VERSION "dbc-export 1 2026.26.6.5"

NS_ :

BS_:

BU_: ADSP APB APP APS APSB BB BMS CC CMP CMPD CP DAS DI DIF DIR DPB EPAS3P EPAS3S EPASTP EPASTS EPBL EPBR ESP EVSE FC GTW HCML HCMR HVP IBST ICR IDB LS OCS1P ODIN PARK PCS PCS2 PLG PM PMF PMR PNCD PTC RADC RCM RCM2 RCM3 RCU SCCM SCM SCS SDCR TAS TCU TCU2 TPMS TRCM UDS UI UIS UMC USM V2G VC VCBATT VCBATT0 VCBATT1 VCBATT2 VCCC VCFRONT VCFRONT1 VCFRONT2 VCLEFT VCRIGHT VCSEAT2L VCSEAT2R VCSEC VEH

BO_ 2030 TRCM_alertMatrix: 8 TRCM
 SG_ TRCM_matrixIndex M : 0|4@1+ (1,0) [0|15] "" Vector__XXX
 SG_ TRCM_a001_airbagsDisabled m0 : 4|1@1+ (1,0) [0|1] "" Vector__XXX
 SG_ TRCM_a002_systemDisabled m0 : 5|1@1+ (1,0) [0|1] "" Vector__XXX
 SG_ TRCM_a003_SWAssertion m0 : 6|1@1+ (1,0) [0|1] "" Vector__XXX
 SG_ TRCM_a004_internalFailure m0 : 7|1@1+ (1,0) [0|1] "" Vector__XXX
 SG_ TRCM_a005_CANTXError m0 : 8|1@1+ (1,0) [0|1] "" Vector__XXX
 SG_ TRCM_a006_CANTX_cyclicError m0 : 9|1@1+ (1,0) [0|1] "" Vector__XXX
 SG_ TRCM_a007_chassisChecksumError m0 : 10|1@1+ (1,0) [0|1] "" Vector__XXX
 SG_ TRCM_a008_chassisCounterError m0 : 11|1@1+ (1,0) [0|1] "" Vector__XXX
 SG_ TRCM_a009_partyChecksumError m0 : 12|1@1+ (1,0) [0|1] "" Vector__XXX
 SG_ TRCM_a010_partyCounterError m0 : 13|1@1+ (1,0) [0|1] "" Vector__XXX
 SG_ TRCM_a011_edrDataLocked m0 : 14|1@1+ (1,0) [0|1] "" Vector__XXX
 SG_ TRCM_a012_asm5TemperatureOutside m0 : 15|1@1+ (1,0) [0|1] "" Vector__XXX
 SG_ TRCM_a013_AlertManagerFault m0 : 16|1@1+ (1,0) [0|1] "" Vector__XXX
 SG_ TRCM_a014_asm3TemperatureOutside m0 : 17|1@1+ (1,0) [0|1] "" Vector__XXX
 SG_ TRCM_a015_NVMMError m0 : 18|1@1+ (1,0) [0|1] "" Vector__XXX
 SG_ TRCM_a016_NVMMRecordError m0 : 19|1@1+ (1,0) [0|1] "" Vector__XXX
 SG_ TRCM_a017_asm5TemperatureOutside m0 : 20|1@1+ (1,0) [0|1] "" Vector__XXX
 SG_ TRCM_a018_asm3TemperatureOutside m0 : 21|1@1+ (1,0) [0|1] "" Vector__XXX
 SG_ TRCM_a019_Task500usError m0 : 22|1@1+ (1,0) [0|1] "" Vector__XXX
 SG_ TRCM_a020_asm3ComStatusError m0 : 23|1@1+ (1,0) [0|1] "" Vector__XXX
 SG_ TRCM_a021_TaskSchedulerError m0 : 24|1@1+ (1,0) [0|1] "" Vector__XXX
 SG_ TRCM_a022_TaskInitError m0 : 25|1@1+ (1,0) [0|1] "" Vector__XXX
 SG_ TRCM_a023_asm3ArsStatusXError m0 : 26|1@1+ (1,0) [0|1] "" Vector__XXX
 SG_ TRCM_a024_asm3AccStatusError m0 : 27|1@1+ (1,0) [0|1] "" Vector__XXX
 SG_ TRCM_a025_CHCANBusFaults m0 : 28|1@1+ (1,0) [0|1] "" Vector__XXX
 SG_ TRCM_a026_airbagAsicDiagnosticFa m0 : 29|1@1+ (1,0) [0|1] "" Vector__XXX
 SG_ TRCM_a027_airbagAsicDeploymentDi m0 : 30|1@1+ (1,0) [0|1] "" Vector__XXX
 SG_ TRCM_a028_chassisLengthError m0 : 31|1@1+ (1,0) [0|1] "" Vector__XXX
 SG_ TRCM_a030_ECULogUploadRequest m0 : 33|1@1+ (1,0) [0|1] "" Vector__XXX
 SG_ TRCM_a031_UDSActive m0 : 34|1@1+ (1,0) [0|1] "" Vector__XXX
 SG_ TRCM_a032_ScrollCreated m0 : 35|1@1+ (1,0) [0|1] "" Vector__XXX
 SG_ TRCM_a033_HercLogCreated m0 : 36|1@1+ (1,0) [0|1] "" Vector__XXX
 SG_ TRCM_a034_apClipTrigger m0 : 37|1@1+ (1,0) [0|1] "" Vector__XXX
 SG_ TRCM_a035_hvDisconnectCommanded m0 : 38|1@1+ (1,0) [0|1] "" Vector__XXX
 SG_ TRCM_a036_crashDetected m0 : 39|1@1+ (1,0) [0|1] "" Vector__XXX
 SG_ TRCM_a037_nearDeploy m0 : 40|1@1+ (1,0) [0|1] "" Vector__XXX
 SG_ TRCM_a038_ens1Degraded m0 : 41|1@1+ (1,0) [0|1] "" Vector__XXX
 SG_ TRCM_a039_ens2Degraded m0 : 42|1@1+ (1,0) [0|1] "" Vector__XXX
 SG_ TRCM_a040_task500usOverrunDebug m0 : 43|1@1+ (1,0) [0|1] "" Vector__XXX
 SG_ TRCM_a041_HighCPULoad m0 : 44|1@1+ (1,0) [0|1] "" Vector__XXX
 SG_ TRCM_a042_HighStackUsage m0 : 45|1@1+ (1,0) [0|1] "" Vector__XXX
 SG_ TRCM_a043_Task1msError m0 : 46|1@1+ (1,0) [0|1] "" Vector__XXX
 SG_ TRCM_a044_Task10msError m0 : 47|1@1+ (1,0) [0|1] "" Vector__XXX
 SG_ TRCM_a045_Task100msError m0 : 48|1@1+ (1,0) [0|1] "" Vector__XXX
 SG_ TRCM_a046_Task1000msError m0 : 49|1@1+ (1,0) [0|1] "" Vector__XXX
 SG_ TRCM_a047_vinNotLearned m0 : 50|1@1+ (1,0) [0|1] "" Vector__XXX
 SG_ TRCM_a048_vinMismatch m0 : 51|1@1+ (1,0) [0|1] "" Vector__XXX
 SG_ TRCM_a049_nvmDebugInfo m0 : 52|1@1+ (1,0) [0|1] "" Vector__XXX
 SG_ TRCM_a050_partyLengthError m0 : 53|1@1+ (1,0) [0|1] "" Vector__XXX
 SG_ TRCM_a051_systemSelfTestTimeout m0 : 54|1@1+ (1,0) [0|1] "" Vector__XXX
 SG_ TRCM_a057_HVP_MIA m0 : 60|1@1+ (1,0) [0|1] "" Vector__XXX
 SG_ TRCM_a058_inputRHighSyncDebug m0 : 61|1@1+ (1,0) [0|1] "" Vector__XXX
 SG_ TRCM_a059_inputResistanceHigh m0 : 62|1@1+ (1,0) [0|1] "" Vector__XXX
 SG_ TRCM_a060_engineeringBuild m0 : 63|1@1+ (1,0) [0|1] "" Vector__XXX
 SG_ TRCM_a061_XCPConnected m1 : 4|1@1+ (1,0) [0|1] "" Vector__XXX
 SG_ TRCM_a062_XCPWasConnected m1 : 5|1@1+ (1,0) [0|1] "" Vector__XXX
 SG_ TRCM_a063_SwitchFault m1 : 6|1@1+ (1,0) [0|1] "" Vector__XXX
 SG_ TRCM_a064_busSleepReqTimeout m1 : 7|1@1+ (1,0) [0|1] "" Vector__XXX
 SG_ TRCM_a065_vSafingFetUnderVoltage m1 : 8|1@1+ (1,0) [0|1] "" Vector__XXX
 SG_ TRCM_a066_leftPowerIssue m1 : 9|1@1+ (1,0) [0|1] "" Vector__XXX
 SG_ TRCM_a067_rightPowerIssue m1 : 10|1@1+ (1,0) [0|1] "" Vector__XXX
 SG_ TRCM_a068_vBusCUnderVoltage m1 : 11|1@1+ (1,0) [0|1] "" Vector__XXX
 SG_ TRCM_a069_swAppBoot m1 : 12|1@1+ (1,0) [0|1] "" Vector__XXX
 SG_ TRCM_a070_asm3StatusError m1 : 13|1@1+ (1,0) [0|1] "" Vector__XXX
 SG_ TRCM_a071_asm3DeviceFaulted m1 : 14|1@1+ (1,0) [0|1] "" Vector__XXX
 SG_ TRCM_a072_ais2120StatusError m1 : 15|1@1+ (1,0) [0|1] "" Vector__XXX
 SG_ TRCM_a073_ais2120DeviceFaulted m1 : 16|1@1+ (1,0) [0|1] "" Vector__XXX
 SG_ TRCM_a074_ais2120SelfTestXPositi m1 : 17|1@1+ (1,0) [0|1] "" Vector__XXX
 SG_ TRCM_a075_ais2120SelfTestXNegati m1 : 18|1@1+ (1,0) [0|1] "" Vector__XXX
 SG_ TRCM_a076_ais2120SelfTestYPositi m1 : 19|1@1+ (1,0) [0|1] "" Vector__XXX
 SG_ TRCM_a077_ais2120SelfTestYNegati m1 : 20|1@1+ (1,0) [0|1] "" Vector__XXX
 SG_ TRCM_a078_imuSensorSignalMonitor m1 : 21|1@1+ (1,0) [0|1] "" Vector__XXX
 SG_ TRCM_a081_powerLossDetected m1 : 24|1@1+ (1,0) [0|1] "" Vector__XXX
 SG_ TRCM_a082_VCRIGHT_IPC_MIA m1 : 25|1@1+ (1,0) [0|1] "" Vector__XXX
 SG_ TRCM_a083_VCLEFT_IPC_MIA m1 : 26|1@1+ (1,0) [0|1] "" Vector__XXX
 SG_ TRCM_a084_TPMS_MIA m1 : 27|1@1+ (1,0) [0|1] "" Vector__XXX
 SG_ TRCM_a085_CCCM_MIA m1 : 28|1@1+ (1,0) [0|1] "" Vector__XXX
 SG_ TRCM_a086_VCBATT_MIA m1 : 29|1@1+ (1,0) [0|1] "" Vector__XXX
 SG_ TRCM_a087_DIREL_MIA m1 : 30|1@1+ (1,0) [0|1] "" Vector__XXX
 SG_ TRCM_a088_DIRER_MIA m1 : 31|1@1+ (1,0) [0|1] "" Vector__XXX
 SG_ TRCM_a089_IBST_MIA m1 : 32|1@1+ (1,0) [0|1] "" Vector__XXX
 SG_ TRCM_a090_APS_MIA m1 : 33|1@1+ (1,0) [0|1] "" Vector__XXX
 SG_ TRCM_a091_CMPD_MIA m1 : 34|1@1+ (1,0) [0|1] "" Vector__XXX
 SG_ TRCM_a092_VCSEATD_MIA m1 : 35|1@1+ (1,0) [0|1] "" Vector__XXX
 SG_ TRCM_a093_VCSEATP_MIA m1 : 36|1@1+ (1,0) [0|1] "" Vector__XXX
 SG_ TRCM_a094_EPAS3P_MIA m1 : 37|1@1+ (1,0) [0|1] "" Vector__XXX
 SG_ TRCM_a095_CHG_MIA m1 : 38|1@1+ (1,0) [0|1] "" Vector__XXX
 SG_ TRCM_a096_OCS1P_MIA m1 : 39|1@1+ (1,0) [0|1] "" Vector__XXX
 SG_ TRCM_a097_CMP_MIA m1 : 40|1@1+ (1,0) [0|1] "" Vector__XXX
 SG_ TRCM_a098_DIR_MIA m1 : 41|1@1+ (1,0) [0|1] "" Vector__XXX
 SG_ TRCM_a099_PARK_MIA m1 : 42|1@1+ (1,0) [0|1] "" Vector__XXX
 SG_ TRCM_a100_CANbus_MIA m1 : 43|1@1+ (1,0) [0|1] "" Vector__XXX
 SG_ TRCM_a101_PM_MIA m1 : 44|1@1+ (1,0) [0|1] "" Vector__XXX
 SG_ TRCM_a102_PTC_MIA m1 : 45|1@1+ (1,0) [0|1] "" Vector__XXX
 SG_ TRCM_a103_CP_MIA m1 : 46|1@1+ (1,0) [0|1] "" Vector__XXX
 SG_ TRCM_a104_DAS_MIA m1 : 47|1@1+ (1,0) [0|1] "" Vector__XXX
 SG_ TRCM_a105_TAS_MIA m1 : 48|1@1+ (1,0) [0|1] "" Vector__XXX
 SG_ TRCM_a106_PCS_MIA m1 : 49|1@1+ (1,0) [0|1] "" Vector__XXX
 SG_ TRCM_a107_BMS_MIA m1 : 50|1@1+ (1,0) [0|1] "" Vector__XXX
 SG_ TRCM_a108_DIF_MIA m1 : 51|1@1+ (1,0) [0|1] "" Vector__XXX
 SG_ TRCM_a109_RCM_MIA m1 : 52|1@1+ (1,0) [0|1] "" Vector__XXX
 SG_ TRCM_a110_GTW_MIA m1 : 53|1@1+ (1,0) [0|1] "" Vector__XXX
 SG_ TRCM_a111_EPBR_MIA m1 : 54|1@1+ (1,0) [0|1] "" Vector__XXX
 SG_ TRCM_a112_EPBL_MIA m1 : 55|1@1+ (1,0) [0|1] "" Vector__XXX
 SG_ TRCM_a113_UI_MIA m1 : 56|1@1+ (1,0) [0|1] "" Vector__XXX
 SG_ TRCM_a114_ESP_MIA m1 : 57|1@1+ (1,0) [0|1] "" Vector__XXX
 SG_ TRCM_a115_VCSEC_MIA m1 : 58|1@1+ (1,0) [0|1] "" Vector__XXX
 SG_ TRCM_a116_VCRIGHT_MIA m1 : 59|1@1+ (1,0) [0|1] "" Vector__XXX
 SG_ TRCM_a117_VCLEFT_MIA m1 : 60|1@1+ (1,0) [0|1] "" Vector__XXX
 SG_ TRCM_a118_VCFRONT_MIA m1 : 61|1@1+ (1,0) [0|1] "" Vector__XXX
 SG_ TRCM_a119_SCCM_MIA m1 : 62|1@1+ (1,0) [0|1] "" Vector__XXX
 SG_ TRCM_a120_DI_DRIVE_MIA m1 : 63|1@1+ (1,0) [0|1] "" Vector__XXX
 SG_ TRCM_a121_buckleStatusFrontLeftS m2 : 4|1@1+ (1,0) [0|1] "" Vector__XXX
 SG_ TRCM_a122_buckleStatusFrontRight m2 : 5|1@1+ (1,0) [0|1] "" Vector__XXX
 SG_ TRCM_a123_buckleStatusRearLeftSi m2 : 6|1@1+ (1,0) [0|1] "" Vector__XXX
 SG_ TRCM_a124_buckleStatusRearRightS m2 : 7|1@1+ (1,0) [0|1] "" Vector__XXX
 SG_ TRCM_a125_occupantClassification m2 : 8|1@1+ (1,0) [0|1] "" Vector__XXX
 SG_ TRCM_a126_seatTrackPositionLeftS m2 : 9|1@1+ (1,0) [0|1] "" Vector__XXX
 SG_ TRCM_a127_seatTrackPositionRight m2 : 10|1@1+ (1,0) [0|1] "" Vector__XXX
 SG_ TRCM_a135_asm5StatusError m2 : 18|1@1+ (1,0) [0|1] "" Vector__XXX
 SG_ TRCM_a136_asm5DeviceFaulted m2 : 19|1@1+ (1,0) [0|1] "" Vector__XXX
 SG_ TRCM_a137_ext1AsicSnoopTestFaile m2 : 20|1@1+ (1,0) [0|1] "" Vector__XXX
 SG_ TRCM_a138_ext2AsicSnoopTestFaile m2 : 21|1@1+ (1,0) [0|1] "" Vector__XXX
 SG_ TRCM_a145_frontCenterAccelReport m2 : 28|1@1+ (1,0) [0|1] "" Vector__XXX
 SG_ TRCM_a146_frontCenterAccelGenera m2 : 29|1@1+ (1,0) [0|1] "" Vector__XXX
 SG_ TRCM_a147_frontCenterAccelElectr m2 : 30|1@1+ (1,0) [0|1] "" Vector__XXX
 SG_ TRCM_a148_frontCenterAccelConfig m2 : 31|1@1+ (1,0) [0|1] "" Vector__XXX
 SG_ TRCM_a149_frontCenterAccelSignal m2 : 32|1@1+ (1,0) [0|1] "" Vector__XXX
 SG_ TRCM_a150_frontLeftAccelReported m2 : 33|1@1+ (1,0) [0|1] "" Vector__XXX
 SG_ TRCM_a151_frontLeftAccelGeneralI m2 : 34|1@1+ (1,0) [0|1] "" Vector__XXX
 SG_ TRCM_a152_frontLeftAccelElectric m2 : 35|1@1+ (1,0) [0|1] "" Vector__XXX
 SG_ TRCM_a153_frontLeftAccelConfigEr m2 : 36|1@1+ (1,0) [0|1] "" Vector__XXX
 SG_ TRCM_a154_frontLeftAccelSignalMo m2 : 37|1@1+ (1,0) [0|1] "" Vector__XXX
 SG_ TRCM_a155_frontLeftDoorPressureR m2 : 38|1@1+ (1,0) [0|1] "" Vector__XXX
 SG_ TRCM_a156_frontLeftDoorPressureG m2 : 39|1@1+ (1,0) [0|1] "" Vector__XXX
 SG_ TRCM_a157_frontLeftDoorPressureE m2 : 40|1@1+ (1,0) [0|1] "" Vector__XXX
 SG_ TRCM_a158_frontLeftDoorPressureC m2 : 41|1@1+ (1,0) [0|1] "" Vector__XXX
 SG_ TRCM_a159_frontLeftDoorPressureS m2 : 42|1@1+ (1,0) [0|1] "" Vector__XXX
 SG_ TRCM_a160_frontRightAccelReporte m2 : 43|1@1+ (1,0) [0|1] "" Vector__XXX
 SG_ TRCM_a161_frontRightAccelGeneral m2 : 44|1@1+ (1,0) [0|1] "" Vector__XXX
 SG_ TRCM_a162_frontRightAccelElectri m2 : 45|1@1+ (1,0) [0|1] "" Vector__XXX
 SG_ TRCM_a163_frontRightAccelConfigE m2 : 46|1@1+ (1,0) [0|1] "" Vector__XXX
 SG_ TRCM_a164_frontRightAccelSignalM m2 : 47|1@1+ (1,0) [0|1] "" Vector__XXX
 SG_ TRCM_a165_frontRightDoorPressure m2 : 48|1@1+ (1,0) [0|1] "" Vector__XXX
 SG_ TRCM_a166_frontRightDoorPressure m2 : 49|1@1+ (1,0) [0|1] "" Vector__XXX
 SG_ TRCM_a167_frontRightDoorPressure m2 : 50|1@1+ (1,0) [0|1] "" Vector__XXX
 SG_ TRCM_a168_frontRightDoorPressure m2 : 51|1@1+ (1,0) [0|1] "" Vector__XXX
 SG_ TRCM_a169_frontRightDoorPressure m2 : 52|1@1+ (1,0) [0|1] "" Vector__XXX
 SG_ TRCM_a170_leftBPillarAccelReport m2 : 53|1@1+ (1,0) [0|1] "" Vector__XXX
 SG_ TRCM_a171_leftBPillarAccelGenera m2 : 54|1@1+ (1,0) [0|1] "" Vector__XXX
 SG_ TRCM_a172_leftBPillarAccelElectr m2 : 55|1@1+ (1,0) [0|1] "" Vector__XXX
 SG_ TRCM_a173_leftBPillarAccelConfig m2 : 56|1@1+ (1,0) [0|1] "" Vector__XXX
 SG_ TRCM_a174_leftBPillarAccelSignal m2 : 57|1@1+ (1,0) [0|1] "" Vector__XXX
 SG_ TRCM_a175_leftCPillarAccelReport m2 : 58|1@1+ (1,0) [0|1] "" Vector__XXX
 SG_ TRCM_a176_leftCPillarAccelGenera m2 : 59|1@1+ (1,0) [0|1] "" Vector__XXX
 SG_ TRCM_a177_leftCPillarAccelElectr m2 : 60|1@1+ (1,0) [0|1] "" Vector__XXX
 SG_ TRCM_a178_leftCPillarAccelConfig m2 : 61|1@1+ (1,0) [0|1] "" Vector__XXX
 SG_ TRCM_a179_leftCPillarAccelSignal m2 : 62|1@1+ (1,0) [0|1] "" Vector__XXX
 SG_ TRCM_a190_rearLeftDoorPressureRe m3 : 13|1@1+ (1,0) [0|1] "" Vector__XXX
 SG_ TRCM_a191_rearLeftDoorPressureGe m3 : 14|1@1+ (1,0) [0|1] "" Vector__XXX
 SG_ TRCM_a192_rearLeftDoorPressureEl m3 : 15|1@1+ (1,0) [0|1] "" Vector__XXX
 SG_ TRCM_a193_rearLeftDoorPressureCo m3 : 16|1@1+ (1,0) [0|1] "" Vector__XXX
 SG_ TRCM_a194_rearLeftDoorPressureSi m3 : 17|1@1+ (1,0) [0|1] "" Vector__XXX
 SG_ TRCM_a195_rearRightDoorPressureR m3 : 18|1@1+ (1,0) [0|1] "" Vector__XXX
 SG_ TRCM_a196_rearRightDoorPressureG m3 : 19|1@1+ (1,0) [0|1] "" Vector__XXX
 SG_ TRCM_a197_rearRightDoorPressureE m3 : 20|1@1+ (1,0) [0|1] "" Vector__XXX
 SG_ TRCM_a198_rearRightDoorPressureC m3 : 21|1@1+ (1,0) [0|1] "" Vector__XXX
 SG_ TRCM_a199_rearRightDoorPressureS m3 : 22|1@1+ (1,0) [0|1] "" Vector__XXX
 SG_ TRCM_a200_rightBPillarAccelRepor m3 : 23|1@1+ (1,0) [0|1] "" Vector__XXX
 SG_ TRCM_a201_rightBPillarAccelGener m3 : 24|1@1+ (1,0) [0|1] "" Vector__XXX
 SG_ TRCM_a202_rightBPillarAccelElect m3 : 25|1@1+ (1,0) [0|1] "" Vector__XXX
 SG_ TRCM_a203_rightBPillarAccelConfi m3 : 26|1@1+ (1,0) [0|1] "" Vector__XXX
 SG_ TRCM_a204_rightBPillarAccelSigna m3 : 27|1@1+ (1,0) [0|1] "" Vector__XXX
 SG_ TRCM_a205_rightCPillarAccelRepor m3 : 28|1@1+ (1,0) [0|1] "" Vector__XXX
 SG_ TRCM_a206_rightCPillarAccelGener m3 : 29|1@1+ (1,0) [0|1] "" Vector__XXX
 SG_ TRCM_a207_rightCPillarAccelElect m3 : 30|1@1+ (1,0) [0|1] "" Vector__XXX
 SG_ TRCM_a208_rightCPillarAccelConfi m3 : 31|1@1+ (1,0) [0|1] "" Vector__XXX
 SG_ TRCM_a209_rightCPillarAccelSigna m3 : 32|1@1+ (1,0) [0|1] "" Vector__XXX
 SG_ TRCM_a272_asm5ComStatusError m4 : 35|1@1+ (1,0) [0|1] "" Vector__XXX
 SG_ TRCM_a273_asm5ArsStatusXError m4 : 36|1@1+ (1,0) [0|1] "" Vector__XXX
 SG_ TRCM_a274_asm5ArsStatusZError m4 : 37|1@1+ (1,0) [0|1] "" Vector__XXX
 SG_ TRCM_a275_asm5AccStatusError m4 : 38|1@1+ (1,0) [0|1] "" Vector__XXX
 SG_ TRCM_a276_watchdogStatus m4 : 39|1@1+ (1,0) [0|1] "" Vector__XXX
 SG_ TRCM_a278_safingEngine0Armed m4 : 41|1@1+ (1,0) [0|1] "" Vector__XXX
 SG_ TRCM_a279_safingEngine1Armed m4 : 42|1@1+ (1,0) [0|1] "" Vector__XXX
 SG_ TRCM_a280_safingEngine2Armed m4 : 43|1@1+ (1,0) [0|1] "" Vector__XXX
 SG_ TRCM_a281_safingEngine3Armed m4 : 44|1@1+ (1,0) [0|1] "" Vector__XXX
 SG_ TRCM_a282_safingEngine4Armed m4 : 45|1@1+ (1,0) [0|1] "" Vector__XXX
 SG_ TRCM_a283_safingEngine5Armed m4 : 46|1@1+ (1,0) [0|1] "" Vector__XXX
 SG_ TRCM_a284_safingEngine6Armed m4 : 47|1@1+ (1,0) [0|1] "" Vector__XXX
 SG_ TRCM_a285_safingEngine7Armed m4 : 48|1@1+ (1,0) [0|1] "" Vector__XXX
 SG_ TRCM_a286_safingEngine8Armed m4 : 49|1@1+ (1,0) [0|1] "" Vector__XXX
 SG_ TRCM_a287_safingEngine9Armed m4 : 50|1@1+ (1,0) [0|1] "" Vector__XXX
 SG_ TRCM_a288_safingEngine10Armed m4 : 51|1@1+ (1,0) [0|1] "" Vector__XXX
 SG_ TRCM_a289_safingEngine11Armed m4 : 52|1@1+ (1,0) [0|1] "" Vector__XXX
 SG_ TRCM_a290_safingEngine12Armed m4 : 53|1@1+ (1,0) [0|1] "" Vector__XXX
 SG_ TRCM_a291_safingEngine13Armed m4 : 54|1@1+ (1,0) [0|1] "" Vector__XXX
 SG_ TRCM_a292_safingEngine14Armed m4 : 55|1@1+ (1,0) [0|1] "" Vector__XXX
 SG_ TRCM_a293_safingEngine15Armed m4 : 56|1@1+ (1,0) [0|1] "" Vector__XXX
 SG_ TRCM_a294_safingEngine16Armed m4 : 57|1@1+ (1,0) [0|1] "" Vector__XXX
 SG_ TRCM_a295_safingEngine17Armed m4 : 58|1@1+ (1,0) [0|1] "" Vector__XXX
 SG_ TRCM_a296_safingEngine18Armed m4 : 59|1@1+ (1,0) [0|1] "" Vector__XXX
 SG_ TRCM_a297_safingEngine19Armed m4 : 60|1@1+ (1,0) [0|1] "" Vector__XXX
 SG_ TRCM_a298_safingEngine20Armed m4 : 61|1@1+ (1,0) [0|1] "" Vector__XXX
 SG_ TRCM_a299_safingEngine21Armed m4 : 62|1@1+ (1,0) [0|1] "" Vector__XXX
 SG_ TRCM_a300_driverAirbagStage1Supp m4 : 63|1@1+ (1,0) [0|1] "" Vector__XXX
 SG_ TRCM_a301_passengerAirbagStage1S m5 : 4|1@1+ (1,0) [0|1] "" Vector__XXX
 SG_ TRCM_a302_driverAirbagStage2Supp m5 : 5|1@1+ (1,0) [0|1] "" Vector__XXX
 SG_ TRCM_a303_driverAirbagActiveVent m5 : 6|1@1+ (1,0) [0|1] "" Vector__XXX
 SG_ TRCM_a304_passengerAirbagStage2S m5 : 7|1@1+ (1,0) [0|1] "" Vector__XXX
 SG_ TRCM_a305_passengerAirbagActiveV m5 : 8|1@1+ (1,0) [0|1] "" Vector__XXX
 SG_ TRCM_a306_inboardSeatAirbagSuppr m5 : 9|1@1+ (1,0) [0|1] "" Vector__XXX
 SG_ TRCM_a308_kneeAirbagLeftSuppress m5 : 11|1@1+ (1,0) [0|1] "" Vector__XXX
 SG_ TRCM_a309_kneeAirbagRightSuppres m5 : 12|1@1+ (1,0) [0|1] "" Vector__XXX
 SG_ TRCM_a310_curtainAirbagLeftSuppr m5 : 13|1@1+ (1,0) [0|1] "" Vector__XXX
 SG_ TRCM_a311_curtainAirbagRightSupp m5 : 14|1@1+ (1,0) [0|1] "" Vector__XXX
 SG_ TRCM_a312_seatbeltLoadLimiterFro m5 : 15|1@1+ (1,0) [0|1] "" Vector__XXX
 SG_ TRCM_a313_seatbeltLoadLimiterFro m5 : 16|1@1+ (1,0) [0|1] "" Vector__XXX
 SG_ TRCM_a314_seatbeltShoulderPreten m5 : 17|1@1+ (1,0) [0|1] "" Vector__XXX
 SG_ TRCM_a315_seatbeltShoulderPreten m5 : 18|1@1+ (1,0) [0|1] "" Vector__XXX
 SG_ TRCM_a316_seatbeltLapPretensione m5 : 19|1@1+ (1,0) [0|1] "" Vector__XXX
 SG_ TRCM_a317_seatbeltLapPretensione m5 : 20|1@1+ (1,0) [0|1] "" Vector__XXX
 SG_ TRCM_a318_outboardSeatAirbagLeft m5 : 21|1@1+ (1,0) [0|1] "" Vector__XXX
 SG_ TRCM_a319_outboardSeatAirbagRigh m5 : 22|1@1+ (1,0) [0|1] "" Vector__XXX
 SG_ TRCM_a320_hoodLifterLeftSuppress m5 : 23|1@1+ (1,0) [0|1] "" Vector__XXX
 SG_ TRCM_a321_hoodLifterRightSuppres m5 : 24|1@1+ (1,0) [0|1] "" Vector__XXX
 SG_ TRCM_a322_seatbeltShoulderPreten m5 : 25|1@1+ (1,0) [0|1] "" Vector__XXX
 SG_ TRCM_a323_seatbeltShoulderPreten m5 : 26|1@1+ (1,0) [0|1] "" Vector__XXX
 SG_ TRCM_a332_driverAirbagStage1Depl m5 : 35|1@1+ (1,0) [0|1] "" Vector__XXX
 SG_ TRCM_a333_passengerAirbagStage1D m5 : 36|1@1+ (1,0) [0|1] "" Vector__XXX
 SG_ TRCM_a334_driverAirbagStage2Depl m5 : 37|1@1+ (1,0) [0|1] "" Vector__XXX
 SG_ TRCM_a335_driverAirbagActiveVent m5 : 38|1@1+ (1,0) [0|1] "" Vector__XXX
 SG_ TRCM_a336_passengerAirbagStage2D m5 : 39|1@1+ (1,0) [0|1] "" Vector__XXX
 SG_ TRCM_a337_passengerAirbagActiveV m5 : 40|1@1+ (1,0) [0|1] "" Vector__XXX
 SG_ TRCM_a338_inboardSeatAirbagDeplo m5 : 41|1@1+ (1,0) [0|1] "" Vector__XXX
 SG_ TRCM_a340_kneeAirbagLeftDeployed m5 : 43|1@1+ (1,0) [0|1] "" Vector__XXX
 SG_ TRCM_a341_kneeAirbagRightDeploye m5 : 44|1@1+ (1,0) [0|1] "" Vector__XXX
 SG_ TRCM_a342_curtainAirbagLeftDeplo m5 : 45|1@1+ (1,0) [0|1] "" Vector__XXX
 SG_ TRCM_a343_curtainAirbagRightDepl m5 : 46|1@1+ (1,0) [0|1] "" Vector__XXX
 SG_ TRCM_a344_seatbeltLoadLimiterFro m5 : 47|1@1+ (1,0) [0|1] "" Vector__XXX
 SG_ TRCM_a345_seatbeltLoadLimiterFro m5 : 48|1@1+ (1,0) [0|1] "" Vector__XXX
 SG_ TRCM_a346_seatbeltShoulderPreten m5 : 49|1@1+ (1,0) [0|1] "" Vector__XXX
 SG_ TRCM_a347_seatbeltShoulderPreten m5 : 50|1@1+ (1,0) [0|1] "" Vector__XXX
 SG_ TRCM_a348_seatbeltLapPretensione m5 : 51|1@1+ (1,0) [0|1] "" Vector__XXX
 SG_ TRCM_a349_seatbeltLapPretensione m5 : 52|1@1+ (1,0) [0|1] "" Vector__XXX
 SG_ TRCM_a350_outboardSeatAirbagLeft m5 : 53|1@1+ (1,0) [0|1] "" Vector__XXX
 SG_ TRCM_a351_outboardSeatAirbagRigh m5 : 54|1@1+ (1,0) [0|1] "" Vector__XXX
 SG_ TRCM_a352_hoodLifterLeftDeployed m5 : 55|1@1+ (1,0) [0|1] "" Vector__XXX
 SG_ TRCM_a353_hoodLifterRightDeploye m5 : 56|1@1+ (1,0) [0|1] "" Vector__XXX
 SG_ TRCM_a354_seatbeltShoulderPreten m5 : 57|1@1+ (1,0) [0|1] "" Vector__XXX
 SG_ TRCM_a355_seatbeltShoulderPreten m5 : 58|1@1+ (1,0) [0|1] "" Vector__XXX
 SG_ TRCM_a364_safingEngine0NoValidDa m6 : 7|1@1+ (1,0) [0|1] "" Vector__XXX
 SG_ TRCM_a365_safingEngine1NoValidDa m6 : 8|1@1+ (1,0) [0|1] "" Vector__XXX
 SG_ TRCM_a366_safingEngine2NoValidDa m6 : 9|1@1+ (1,0) [0|1] "" Vector__XXX
 SG_ TRCM_a367_safingEngine3NoValidDa m6 : 10|1@1+ (1,0) [0|1] "" Vector__XXX
 SG_ TRCM_a368_safingEngine4NoValidDa m6 : 11|1@1+ (1,0) [0|1] "" Vector__XXX
 SG_ TRCM_a369_safingEngine5NoValidDa m6 : 12|1@1+ (1,0) [0|1] "" Vector__XXX
 SG_ TRCM_a370_safingEngine6NoValidDa m6 : 13|1@1+ (1,0) [0|1] "" Vector__XXX
 SG_ TRCM_a371_safingEngine7NoValidDa m6 : 14|1@1+ (1,0) [0|1] "" Vector__XXX
 SG_ TRCM_a372_safingEngine8NoValidDa m6 : 15|1@1+ (1,0) [0|1] "" Vector__XXX
 SG_ TRCM_a373_safingEngine9NoValidDa m6 : 16|1@1+ (1,0) [0|1] "" Vector__XXX
 SG_ TRCM_a374_safingEngine10NoValidD m6 : 17|1@1+ (1,0) [0|1] "" Vector__XXX
 SG_ TRCM_a375_safingEngine11NoValidD m6 : 18|1@1+ (1,0) [0|1] "" Vector__XXX
 SG_ TRCM_a376_safingEngine12NoValidD m6 : 19|1@1+ (1,0) [0|1] "" Vector__XXX
 SG_ TRCM_a377_safingEngine13NoValidD m6 : 20|1@1+ (1,0) [0|1] "" Vector__XXX
 SG_ TRCM_a378_safingEngine14NoValidD m6 : 21|1@1+ (1,0) [0|1] "" Vector__XXX
 SG_ TRCM_a379_safingEngine15NoValidD m6 : 22|1@1+ (1,0) [0|1] "" Vector__XXX
 SG_ TRCM_a380_safingEngine16NoValidD m6 : 23|1@1+ (1,0) [0|1] "" Vector__XXX
 SG_ TRCM_a381_safingEngine17NoValidD m6 : 24|1@1+ (1,0) [0|1] "" Vector__XXX
 SG_ TRCM_a382_safingEngine18NoValidD m6 : 25|1@1+ (1,0) [0|1] "" Vector__XXX
 SG_ TRCM_a383_safingEngine19NoValidD m6 : 26|1@1+ (1,0) [0|1] "" Vector__XXX
 SG_ TRCM_a384_safingEngine20NoValidD m6 : 27|1@1+ (1,0) [0|1] "" Vector__XXX
 SG_ TRCM_a385_safingEngine21NoValidD m6 : 28|1@1+ (1,0) [0|1] "" Vector__XXX
 SG_ TRCM_a387_primaryAsicResetSource m6 : 30|1@1+ (1,0) [0|1] "" Vector__XXX
 SG_ TRCM_a388_cpuLoadHigh m6 : 31|1@1+ (1,0) [0|1] "" Vector__XXX
 SG_ TRCM_a389_asicPwrStatusError m6 : 32|1@1+ (1,0) [0|1] "" Vector__XXX
 SG_ TRCM_a390_systemAsicClockOrOpera m6 : 33|1@1+ (1,0) [0|1] "" Vector__XXX
 SG_ TRCM_a391_extAsic1ClockOrOperati m6 : 34|1@1+ (1,0) [0|1] "" Vector__XXX
 SG_ TRCM_a392_extAsic2ClockOrOperati m6 : 35|1@1+ (1,0) [0|1] "" Vector__XXX
 SG_ TRCM_a393_depAdcConvertRatioErro m6 : 36|1@1+ (1,0) [0|1] "" Vector__XXX
 SG_ TRCM_a394_gspiGlobalStatusWordEr m6 : 37|1@1+ (1,0) [0|1] "" Vector__XXX
 SG_ TRCM_a395_imuUncalibrated m6 : 38|1@1+ (1,0) [0|1] "" Vector__XXX
 SG_ TRCM_a396_spiCommunicationProgra m6 : 39|1@1+ (1,0) [0|1] "" Vector__XXX
 SG_ TRCM_a397_safingMonitorError m6 : 40|1@1+ (1,0) [0|1] "" Vector__XXX
 SG_ TRCM_a398_asicNvmReprogrammed m6 : 41|1@1+ (1,0) [0|1] "" Vector__XXX
 SG_ TRCM_a399_imuCalibrationComplete m6 : 42|1@1+ (1,0) [0|1] "" Vector__XXX
 SG_ TRCM_a400_driverAirbagStage1Issu m6 : 43|1@1+ (1,0) [0|1] "" Vector__XXX
 SG_ TRCM_a401_passengerAirbagStage1I m6 : 44|1@1+ (1,0) [0|1] "" Vector__XXX
 SG_ TRCM_a402_driverAirbagStage2Issu m6 : 45|1@1+ (1,0) [0|1] "" Vector__XXX
 SG_ TRCM_a403_driverAirbagActiveVent m6 : 46|1@1+ (1,0) [0|1] "" Vector__XXX
 SG_ TRCM_a404_passengerAirbagStage2I m6 : 47|1@1+ (1,0) [0|1] "" Vector__XXX
 SG_ TRCM_a405_passengerAirbagActiveV m6 : 48|1@1+ (1,0) [0|1] "" Vector__XXX
 SG_ TRCM_a406_inboardSeatAirbagIssue m6 : 49|1@1+ (1,0) [0|1] "" Vector__XXX
 SG_ TRCM_a408_kneeAirbagLeftIssue m6 : 51|1@1+ (1,0) [0|1] "" Vector__XXX
 SG_ TRCM_a409_kneeAirbagRightIssue m6 : 52|1@1+ (1,0) [0|1] "" Vector__XXX
 SG_ TRCM_a410_curtainAirbagLeftIssue m6 : 53|1@1+ (1,0) [0|1] "" Vector__XXX
 SG_ TRCM_a411_curtainAirbagRightIssu m6 : 54|1@1+ (1,0) [0|1] "" Vector__XXX
 SG_ TRCM_a412_seatbeltLoadLimiterFro m6 : 55|1@1+ (1,0) [0|1] "" Vector__XXX
 SG_ TRCM_a413_seatbeltLoadLimiterFro m6 : 56|1@1+ (1,0) [0|1] "" Vector__XXX
 SG_ TRCM_a414_seatbeltShoulderPreten m6 : 57|1@1+ (1,0) [0|1] "" Vector__XXX
 SG_ TRCM_a415_seatbeltShoulderPreten m6 : 58|1@1+ (1,0) [0|1] "" Vector__XXX
 SG_ TRCM_a416_seatbeltLapPretensione m6 : 59|1@1+ (1,0) [0|1] "" Vector__XXX
 SG_ TRCM_a417_seatbeltLapPretensione m6 : 60|1@1+ (1,0) [0|1] "" Vector__XXX
 SG_ TRCM_a418_outboardSeatAirbagLeft m6 : 61|1@1+ (1,0) [0|1] "" Vector__XXX
 SG_ TRCM_a419_outboardSeatAirbagRigh m6 : 62|1@1+ (1,0) [0|1] "" Vector__XXX
 SG_ TRCM_a420_hoodLifterLeftIssue m6 : 63|1@1+ (1,0) [0|1] "" Vector__XXX
 SG_ TRCM_a421_hoodLifterRightIssue m7 : 4|1@1+ (1,0) [0|1] "" Vector__XXX
 SG_ TRCM_a422_seatbeltShoulderPreten m7 : 5|1@1+ (1,0) [0|1] "" Vector__XXX
 SG_ TRCM_a423_seatbeltShoulderPreten m7 : 6|1@1+ (1,0) [0|1] "" Vector__XXX
 SG_ TRCM_a432_driverAirbagStage1Conf m7 : 15|1@1+ (1,0) [0|1] "" Vector__XXX
 SG_ TRCM_a433_passengerAirbagStage1C m7 : 16|1@1+ (1,0) [0|1] "" Vector__XXX
 SG_ TRCM_a434_driverAirbagStage2Conf m7 : 17|1@1+ (1,0) [0|1] "" Vector__XXX
 SG_ TRCM_a435_driverAirbagActiveVent m7 : 18|1@1+ (1,0) [0|1] "" Vector__XXX
 SG_ TRCM_a436_passengerAirbagStage2C m7 : 19|1@1+ (1,0) [0|1] "" Vector__XXX
 SG_ TRCM_a437_passengerAirbagActiveV m7 : 20|1@1+ (1,0) [0|1] "" Vector__XXX
 SG_ TRCM_a438_inboardSeatAirbagConfi m7 : 21|1@1+ (1,0) [0|1] "" Vector__XXX
 SG_ TRCM_a440_kneeAirbagLeftConfigEr m7 : 23|1@1+ (1,0) [0|1] "" Vector__XXX
 SG_ TRCM_a441_kneeAirbagRightConfigE m7 : 24|1@1+ (1,0) [0|1] "" Vector__XXX
 SG_ TRCM_a442_curtainAirbagLeftConfi m7 : 25|1@1+ (1,0) [0|1] "" Vector__XXX
 SG_ TRCM_a443_curtainAirbagRightConf m7 : 26|1@1+ (1,0) [0|1] "" Vector__XXX
 SG_ TRCM_a444_seatbeltLoadLimiterFro m7 : 27|1@1+ (1,0) [0|1] "" Vector__XXX
 SG_ TRCM_a445_seatbeltLoadLimiterFro m7 : 28|1@1+ (1,0) [0|1] "" Vector__XXX
 SG_ TRCM_a446_seatbeltShoulderPreten m7 : 29|1@1+ (1,0) [0|1] "" Vector__XXX
 SG_ TRCM_a447_seatbeltShoulderPreten m7 : 30|1@1+ (1,0) [0|1] "" Vector__XXX
 SG_ TRCM_a448_seatbeltLapPretensione m7 : 31|1@1+ (1,0) [0|1] "" Vector__XXX
 SG_ TRCM_a449_seatbeltLapPretensione m7 : 32|1@1+ (1,0) [0|1] "" Vector__XXX
 SG_ TRCM_a450_outboardSeatAirbagLeft m7 : 33|1@1+ (1,0) [0|1] "" Vector__XXX
 SG_ TRCM_a451_outboardSeatAirbagRigh m7 : 34|1@1+ (1,0) [0|1] "" Vector__XXX
 SG_ TRCM_a452_hoodLifterLeftConfigEr m7 : 35|1@1+ (1,0) [0|1] "" Vector__XXX
 SG_ TRCM_a453_hoodLifterRightConfigE m7 : 36|1@1+ (1,0) [0|1] "" Vector__XXX
 SG_ TRCM_a454_seatbeltShoulderPreten m7 : 37|1@1+ (1,0) [0|1] "" Vector__XXX
 SG_ TRCM_a455_seatbeltShoulderPreten m7 : 38|1@1+ (1,0) [0|1] "" Vector__XXX
 SG_ TRCM_a544_erCapDiagnosticsFailed m9 : 7|1@1+ (1,0) [0|1] "" Vector__XXX
 SG_ TRCM_a545_erCapBelowAutarkyThres m9 : 8|1@1+ (1,0) [0|1] "" Vector__XXX
 SG_ TRCM_a546_sensorValuesFaultedByS m9 : 9|1@1+ (1,0) [0|1] "" Vector__XXX
 SG_ TRCM_a550_AlgoWake_RCM_WAKE_FRON m9 : 13|1@1+ (1,0) [0|1] "" Vector__XXX
 SG_ TRCM_a551_AlgoWake_RCM_WAKE_REAR m9 : 14|1@1+ (1,0) [0|1] "" Vector__XXX
 SG_ TRCM_a552_AlgoWake_RCM_WAKE_LEFT m9 : 15|1@1+ (1,0) [0|1] "" Vector__XXX
 SG_ TRCM_a553_AlgoWake_RCM_WAKE_RIGH m9 : 16|1@1+ (1,0) [0|1] "" Vector__XXX
 SG_ TRCM_a554_AlgoWake_PAS_LH_PLAUSI m9 : 17|1@1+ (1,0) [0|1] "" Vector__XXX
 SG_ TRCM_a555_AlgoWake_PAS_LH_PLAUSI m9 : 18|1@1+ (1,0) [0|1] "" Vector__XXX
 SG_ TRCM_a557_AlgoWake_PAS_RH_PLAUSI m9 : 20|1@1+ (1,0) [0|1] "" Vector__XXX
 SG_ TRCM_a558_AlgoWake_PAS_RH_PLAUSI m9 : 21|1@1+ (1,0) [0|1] "" Vector__XXX
 SG_ TRCM_a560_AlgoWake_RCM_WAKE_ROLL m9 : 23|1@1+ (1,0) [0|1] "" Vector__XXX
 SG_ TRCM_a561_AlgoWake_RCM_WAKE_ROLL m9 : 24|1@1+ (1,0) [0|1] "" Vector__XXX
 SG_ TRCM_a562_AlgoWake_RCM_AWAKE_FRO m9 : 25|1@1+ (1,0) [0|1] "" Vector__XXX
 SG_ TRCM_a563_AlgoWake_RCM_AWAKE_REA m9 : 26|1@1+ (1,0) [0|1] "" Vector__XXX
 SG_ TRCM_a564_AlgoWake_RCM_AWAKE_LEF m9 : 27|1@1+ (1,0) [0|1] "" Vector__XXX
 SG_ TRCM_a565_AlgoWake_RCM_AWAKE_RIG m9 : 28|1@1+ (1,0) [0|1] "" Vector__XXX
 SG_ TRCM_a566_AlgoWake_RCM_AWAKE_ROL m9 : 29|1@1+ (1,0) [0|1] "" Vector__XXX
 SG_ TRCM_a567_AlgoWake_RCM_AWAKE_X m9 : 30|1@1+ (1,0) [0|1] "" Vector__XXX
 SG_ TRCM_a568_AlgoWake_RCM_AWAKE_Y m9 : 31|1@1+ (1,0) [0|1] "" Vector__XXX
 SG_ TRCM_a569_AlgoWake_PAS_WAKE_LEFT m9 : 32|1@1+ (1,0) [0|1] "" Vector__XXX
 SG_ TRCM_a570_AlgoWake_PAS_WAKE_RIGH m9 : 33|1@1+ (1,0) [0|1] "" Vector__XXX
 SG_ TRCM_a576_AlgoWake_IMPACT_FINISH m9 : 39|1@1+ (1,0) [0|1] "" Vector__XXX
 SG_ TRCM_a577_AlgoWake_IMPACT_FINISH m9 : 40|1@1+ (1,0) [0|1] "" Vector__XXX
 SG_ TRCM_a578_AlgoWake_IMPACT_FINISH m9 : 41|1@1+ (1,0) [0|1] "" Vector__XXX
 SG_ TRCM_a579_AlgoWake_RCM_ENABLED_X m9 : 42|1@1+ (1,0) [0|1] "" Vector__XXX
 SG_ TRCM_a580_AlgoWake_RCM_ENABLED_Y m9 : 43|1@1+ (1,0) [0|1] "" Vector__XXX
 SG_ TRCM_a581_AlgoWake_RCM_ENABLED_R m9 : 44|1@1+ (1,0) [0|1] "" Vector__XXX
 SG_ TRCM_a582_AlgoWake_RCM_AWAKE m9 : 45|1@1+ (1,0) [0|1] "" Vector__XXX
 SG_ TRCM_a588_yawRateOffsetPosLimit m9 : 51|1@1+ (1,0) [0|1] "" Vector__XXX
 SG_ TRCM_a589_yawRateOffsetNegLimit m9 : 52|1@1+ (1,0) [0|1] "" Vector__XXX
 SG_ TRCM_a590_pitchRateOffsetPosLimi m9 : 53|1@1+ (1,0) [0|1] "" Vector__XXX
 SG_ TRCM_a591_pitchRateOffsetNegLimi m9 : 54|1@1+ (1,0) [0|1] "" Vector__XXX
 SG_ TRCM_a592_rollRateOffsetPosLimit m9 : 55|1@1+ (1,0) [0|1] "" Vector__XXX
 SG_ TRCM_a593_rollRateOffsetNegLimit m9 : 56|1@1+ (1,0) [0|1] "" Vector__XXX
 SG_ TRCM_a594_longitudinalAccelOffse m9 : 57|1@1+ (1,0) [0|1] "" Vector__XXX
 SG_ TRCM_a595_longitudinalAccelOffse m9 : 58|1@1+ (1,0) [0|1] "" Vector__XXX
 SG_ TRCM_a596_lateralAccelOffsetPosL m9 : 59|1@1+ (1,0) [0|1] "" Vector__XXX
 SG_ TRCM_a597_lateralAccelOffsetNegL m9 : 60|1@1+ (1,0) [0|1] "" Vector__XXX
 SG_ TRCM_a598_verticalAccelOffsetPos m9 : 61|1@1+ (1,0) [0|1] "" Vector__XXX
 SG_ TRCM_a599_verticalAccelOffsetNeg m9 : 62|1@1+ (1,0) [0|1] "" Vector__XXX
 SG_ TRCM_a600_airbagAsicStartupFailu m9 : 63|1@1+ (1,0) [0|1] "" Vector__XXX
 SG_ TRCM_a601_loop0AsicStartupDiagno m10 : 4|1@1+ (1,0) [0|1] "" Vector__XXX
 SG_ TRCM_a602_loop1AsicStartupDiagno m10 : 5|1@1+ (1,0) [0|1] "" Vector__XXX
 SG_ TRCM_a603_loop2AsicStartupDiagno m10 : 6|1@1+ (1,0) [0|1] "" Vector__XXX
 SG_ TRCM_a604_loop3AsicStartupDiagno m10 : 7|1@1+ (1,0) [0|1] "" Vector__XXX
 SG_ TRCM_a605_loop4AsicStartupDiagno m10 : 8|1@1+ (1,0) [0|1] "" Vector__XXX
 SG_ TRCM_a606_loop5AsicStartupDiagno m10 : 9|1@1+ (1,0) [0|1] "" Vector__XXX
 SG_ TRCM_a607_loop6AsicStartupDiagno m10 : 10|1@1+ (1,0) [0|1] "" Vector__XXX
 SG_ TRCM_a608_loop7AsicStartupDiagno m10 : 11|1@1+ (1,0) [0|1] "" Vector__XXX
 SG_ TRCM_a609_loop8AsicStartupDiagno m10 : 12|1@1+ (1,0) [0|1] "" Vector__XXX
 SG_ TRCM_a610_loop9AsicStartupDiagno m10 : 13|1@1+ (1,0) [0|1] "" Vector__XXX
 SG_ TRCM_a611_loop10AsicStartupDiagn m10 : 14|1@1+ (1,0) [0|1] "" Vector__XXX
 SG_ TRCM_a612_loop11AsicStartupDiagn m10 : 15|1@1+ (1,0) [0|1] "" Vector__XXX
 SG_ TRCM_a613_loop12AsicStartupDiagn m10 : 16|1@1+ (1,0) [0|1] "" Vector__XXX
 SG_ TRCM_a614_loop13AsicStartupDiagn m10 : 17|1@1+ (1,0) [0|1] "" Vector__XXX
 SG_ TRCM_a615_loop14AsicStartupDiagn m10 : 18|1@1+ (1,0) [0|1] "" Vector__XXX
 SG_ TRCM_a616_loop15AsicStartupDiagn m10 : 19|1@1+ (1,0) [0|1] "" Vector__XXX
 SG_ TRCM_a617_loop16AsicStartupDiagn m10 : 20|1@1+ (1,0) [0|1] "" Vector__XXX
 SG_ TRCM_a618_loop17AsicStartupDiagn m10 : 21|1@1+ (1,0) [0|1] "" Vector__XXX
 SG_ TRCM_a619_loop18AsicStartupDiagn m10 : 22|1@1+ (1,0) [0|1] "" Vector__XXX
 SG_ TRCM_a620_loop19AsicStartupDiagn m10 : 23|1@1+ (1,0) [0|1] "" Vector__XXX
 SG_ TRCM_a621_loop20AsicStartupDiagn m10 : 24|1@1+ (1,0) [0|1] "" Vector__XXX
 SG_ TRCM_a622_loop21AsicStartupDiagn m10 : 25|1@1+ (1,0) [0|1] "" Vector__XXX
 SG_ TRCM_a623_loop22AsicStartupDiagn m10 : 26|1@1+ (1,0) [0|1] "" Vector__XXX
 SG_ TRCM_a624_loop23AsicStartupDiagn m10 : 27|1@1+ (1,0) [0|1] "" Vector__XXX
 SG_ TRCM_a625_loop24AsicStartupDiagn m10 : 28|1@1+ (1,0) [0|1] "" Vector__XXX
 SG_ TRCM_a626_loop25AsicStartupDiagn m10 : 29|1@1+ (1,0) [0|1] "" Vector__XXX
 SG_ TRCM_a627_loop26AsicStartupDiagn m10 : 30|1@1+ (1,0) [0|1] "" Vector__XXX
 SG_ TRCM_a628_loop27AsicStartupDiagn m10 : 31|1@1+ (1,0) [0|1] "" Vector__XXX
 SG_ TRCM_a629_loop28AsicStartupDiagn m10 : 32|1@1+ (1,0) [0|1] "" Vector__XXX
 SG_ TRCM_a630_loop29AsicStartupDiagn m10 : 33|1@1+ (1,0) [0|1] "" Vector__XXX
 SG_ TRCM_a631_loop30AsicStartupDiagn m10 : 34|1@1+ (1,0) [0|1] "" Vector__XXX
 SG_ TRCM_a632_loop31AsicStartupDiagn m10 : 35|1@1+ (1,0) [0|1] "" Vector__XXX
 SG_ TRCM_a633_glacierInitialStatusFa m10 : 36|1@1+ (1,0) [0|1] "" Vector__XXX
 SG_ TRCM_a634_glacierTraceabilityRea m10 : 37|1@1+ (1,0) [0|1] "" Vector__XXX
 SG_ TRCM_a635_glacierTraceabilityRea m10 : 38|1@1+ (1,0) [0|1] "" Vector__XXX
 SG_ TRCM_a636_glacierRegisterPattern m10 : 39|1@1+ (1,0) [0|1] "" Vector__XXX
 SG_ TRCM_a637_glacierFixedPatternSel m10 : 40|1@1+ (1,0) [0|1] "" Vector__XXX
 SG_ TRCM_a638_glacierSelfTestEFailur m10 : 41|1@1+ (1,0) [0|1] "" Vector__XXX
 SG_ TRCM_a639_glacierSelfTestFFailur m10 : 42|1@1+ (1,0) [0|1] "" Vector__XXX
 SG_ TRCM_a640_glacierAnalogSelfTestF m10 : 43|1@1+ (1,0) [0|1] "" Vector__XXX
 SG_ TRCM_a641_glacierOscillatorVerif m10 : 44|1@1+ (1,0) [0|1] "" Vector__XXX
 SG_ TRCM_a642_glacierFinalStatusFail m10 : 45|1@1+ (1,0) [0|1] "" Vector__XXX
 SG_ TRCM_a643_glacierOffsetVerificat m10 : 46|1@1+ (1,0) [0|1] "" Vector__XXX
 SG_ TRCM_a644_glacierNormalOperation m10 : 47|1@1+ (1,0) [0|1] "" Vector__XXX
 SG_ TRCM_a645_glacierDeviceReset m10 : 48|1@1+ (1,0) [0|1] "" Vector__XXX
 SG_ TRCM_a646_glacierDeviceFaulted m10 : 49|1@1+ (1,0) [0|1] "" Vector__XXX

BO_ 2019 TRCM_info: 8 TRCM
 SG_ TRCM_infoIndex M : 0|8@1+ (1,0) [0|255] "" Vector__XXX
 SG_ TRCM_infoBuildType m10 : 8|8@1+ (1,0) [0|255] "" Vector__XXX
 SG_ TRCM_infoBuildConfigId m10 : 16|16@1+ (1,0) [0|65535] "" Vector__XXX
 SG_ TRCM_infoHardwareId m10 : 32|16@1+ (1,0) [0|65535] "" Vector__XXX
 SG_ TRCM_infoComponentId m10 : 48|16@1+ (1,0) [0|65535] "" Vector__XXX
 SG_ TRCM_infoPcbaId m11 : 8|8@1+ (1,0) [0|255] "" Vector__XXX
 SG_ TRCM_infoAssemblyId m11 : 16|8@1+ (1,0) [0|254] "" Vector__XXX
 SG_ TRCM_infoUsageId m11 : 24|16@1+ (1,0) [0|65535] "" Vector__XXX
 SG_ TRCM_infoSubUsageId m11 : 40|16@1+ (1,0) [0|65535] "" Vector__XXX
 SG_ TRCM_infoAppCrc m13 : 8|32@1+ (1,0) [0|4294967295] "" Vector__XXX
 SG_ TRCM_infoAppGitHash m17 : 8|56@1+ (1,0) [0|7.20575940379e+16] "" Vector__XXX
 SG_ TRCM_infoBootGitHash m18 : 8|56@1+ (1,0) [0|7.20575940379e+16] "" Vector__XXX
 SG_ TRCM_infoBootUdsProtoVersion m20 : 8|8@1+ (1,0) [0|255] "" Vector__XXX
 SG_ TRCM_infoBootCrc m20 : 24|32@1+ (1,0) [0|4294967295] "" Vector__XXX

BO_ 1641 UDS_KOSTIAsccmRequest: 8 UDS
 SG_ UDS_KOSTIAsccmRequestData : 7|64@0+ (1,0) [0|1.84467440737e+19] "" Vector__XXX

BO_ 1538 UDS_bmsRequest: 8 UDS
 SG_ UDS_bmsRequestData : 7|64@0+ (1,0) [0|1.84467440737e+19] "" Vector__XXX

BO_ 1579 UDS_ccRequest: 8 UDS
 SG_ UDS_ccRequestData : 7|64@0+ (1,0) [0|1.84467440737e+19] "" Vector__XXX

BO_ 1539 UDS_cmpRequest: 8 UDS
 SG_ UDS_cmpRequestData : 7|64@0+ (1,0) [0|1.84467440737e+19] "" Vector__XXX

BO_ 1543 UDS_cmpdRequest: 8 UDS
 SG_ UDS_cmpdRequestData : 7|64@0+ (1,0) [0|1.84467440737e+19] "" Vector__XXX

BO_ 1550 UDS_cpRequest: 8 UDS
 SG_ UDS_cpRequestData : 7|64@0+ (1,0) [0|1.84467440737e+19] "" Vector__XXX

BO_ 1609 UDS_dasRequest: 8 UDS
 SG_ UDS_dasRequestData : 7|64@0+ (1,0) [0|1.84467440737e+19] "" Vector__XXX

BO_ 1589 UDS_diRequest: 8 UDS
 SG_ UDS_diRequestData : 7|64@0+ (1,0) [0|1.84467440737e+19] "" Vector__XXX

BO_ 1541 UDS_difRequest: 8 UDS
 SG_ UDS_difRequestData : 7|64@0+ (1,0) [0|1.84467440737e+19] "" Vector__XXX

BO_ 1542 UDS_dirRequest: 8 UDS
 SG_ UDS_dirRequestData : 7|64@0+ (1,0) [0|1.84467440737e+19] "" Vector__XXX

BO_ 1584 UDS_epas3pRequest: 8 UDS
 SG_ UDS_epas3pRequestData : 7|64@0+ (1,0) [0|1.84467440737e+19] "" Vector__XXX

BO_ 1840 UDS_epas3sRequest: 8 UDS
 SG_ UDS_epas3sRequestData : 7|64@0+ (1,0) [0|1.84467440737e+19] "" Vector__XXX

BO_ 1572 UDS_epblRequest: 8 UDS
 SG_ UDS_epblRequestData_H : 7|32@0+ (1,0) [0|4294967295] "" Vector__XXX
 SG_ UDS_epblRequestData_L : 39|32@0+ (1,0) [0|4294967295] "" Vector__XXX

BO_ 1574 UDS_epbrRequest: 8 UDS
 SG_ UDS_epbrRequestData_H : 7|32@0+ (1,0) [0|4294967295] "" Vector__XXX
 SG_ UDS_epbrRequestData_L : 39|32@0+ (1,0) [0|4294967295] "" Vector__XXX

BO_ 1605 UDS_espRequest: 8 UDS
 SG_ UDS_espRequestData : 7|64@0+ (1,0) [0|1.84467440737e+19] "" Vector__XXX

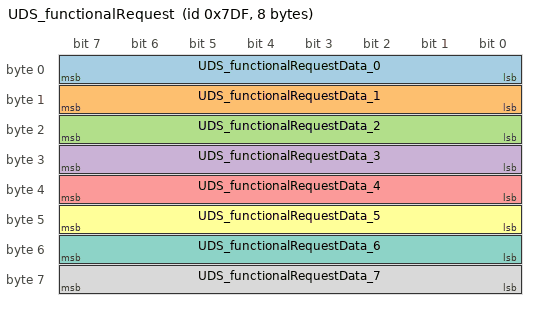
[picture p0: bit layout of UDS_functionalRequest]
BO_ 2015 UDS_functionalRequest: 8 UDS
 SG_ UDS_functionalRequestData_0 : 7|8@0+ (1,0) [0|255] "" Vector__XXX
 SG_ UDS_functionalRequestData_1 : 15|8@0+ (1,0) [0|255] "" Vector__XXX
 SG_ UDS_functionalRequestData_2 : 23|8@0+ (1,0) [0|255] "" Vector__XXX
 SG_ UDS_functionalRequestData_3 : 31|8@0+ (1,0) [0|255] "" Vector__XXX
 SG_ UDS_functionalRequestData_4 : 39|8@0+ (1,0) [0|255] "" Vector__XXX
 SG_ UDS_functionalRequestData_5 : 47|8@0+ (1,0) [0|255] "" Vector__XXX
 SG_ UDS_functionalRequestData_6 : 55|8@0+ (1,0) [0|255] "" Vector__XXX
 SG_ UDS_functionalRequestData_7 : 63|8@0+ (1,0) [0|255] "" Vector__XXX

BO_ 2014 UDS_functionalRequest_CH: 8 UDS
 SG_ UDS_functionalRequestDataCH : 7|64@0+ (1,0) [0|1.84467440737e+19] "" Vector__XXX

BO_ 1552 UDS_hvpRequest: 8 UDS
 SG_ UDS_hvpRequestData : 7|64@0+ (1,0) [0|1.84467440737e+19] "" Vector__XXX

BO_ 1613 UDS_ibstRequest: 8 UDS
 SG_ UDS_ibstRequestData : 7|64@0+ (1,0) [0|1.84467440737e+19] "" Vector__XXX

BO_ 1560 UDS_icrRequest: 8 UDS
 SG_ UDS_icrRequestData : 7|64@0+ (1,0) [0|1.84467440737e+19] "" Vector__XXX

BO_ 1603 UDS_ocs1pRequest: 8 UDS
 SG_ UDS_ocs1pRequestData : 7|64@0+ (1,0) [0|1.84467440737e+19] "" Vector__XXX

BO_ 1614 UDS_parkRequest: 8 UDS
 SG_ UDS_parkRequestData : 7|64@0+ (1,0) [0|1.84467440737e+19] "" Vector__XXX

BO_ 1576 UDS_pcsRequest: 8 UDS
 SG_ UDS_pcsRequestData : 7|64@0+ (1,0) [0|1.84467440737e+19] "" Vector__XXX

BO_ 1634 UDS_plgRequest: 8 UDS
 SG_ UDS_plgRequestData : 7|64@0+ (1,0) [0|1.84467440737e+19] "" Vector__XXX

BO_ 1568 UDS_pmRequest: 8 UDS
 SG_ UDS_pmRequestData : 7|64@0+ (1,0) [0|1.84467440737e+19] "" Vector__XXX

BO_ 1604 UDS_pmfRequest: 8 UDS
 SG_ UDS_pmfRequestData : 7|64@0+ (1,0) [0|1.84467440737e+19] "" Vector__XXX

BO_ 1540 UDS_pmrRequest: 8 UDS
 SG_ UDS_pmrRequestData : 7|64@0+ (1,0) [0|1.84467440737e+19] "" Vector__XXX

BO_ 1734 UDS_ptcRequest: 8 UDS
 SG_ UDS_ptcRequestData : 7|64@0+ (1,0) [0|1.84467440737e+19] "" Vector__XXX

BO_ 1649 UDS_radcRequest: 8 UDS
 SG_ UDS_radcRequestData : 7|64@0+ (1,0) [0|1.84467440737e+19] "" Vector__XXX

BO_ 1601 UDS_rcmRequest: 8 UDS
 SG_ UDS_rcmRequestData : 7|64@0+ (1,0) [0|1.84467440737e+19] "" Vector__XXX

BO_ 1664 UDS_sccmRequest: 8 UDS
 SG_ UDS_sccmRequestData : 7|64@0+ (1,0) [0|1.84467440737e+19] "" Vector__XXX

BO_ 1723 UDS_sdcrRequest: 8 UDS
 SG_ UDS_sdcrRequestData : 7|64@0+ (1,0) [0|1.84467440737e+19] "" Vector__XXX

BO_ 1611 UDS_tasRequest: 8 UDS
 SG_ UDS_tasRequestData : 7|64@0+ (1,0) [0|1.84467440737e+19] "" Vector__XXX

BO_ 1551 UDS_thcRequest: 8 UDS
 SG_ UDS_thcRequestData_H : 7|32@0+ (1,0) [0|4294967295] "" Vector__XXX
 SG_ UDS_thcRequestData_L : 39|32@0+ (1,0) [0|4294967295] "" Vector__XXX

BO_ 1615 UDS_tpmsRequest: 8 UDS
 SG_ UDS_tpmsRequestData : 7|64@0+ (1,0) [0|1.84467440737e+19] "" Vector__XXX

BO_ 1578 UDS_vcbatt1Request: 8 UDS
 SG_ UDS_vcbatt1RequestData : 7|64@0+ (1,0) [0|1.84467440737e+19] "" Vector__XXX

BO_ 1588 UDS_vcbatt2Request: 8 UDS
 SG_ UDS_vcbatt2RequestData : 7|64@0+ (1,0) [0|1.84467440737e+19] "" Vector__XXX

BO_ 1636 UDS_vcbattRequest: 8 UDS
 SG_ UDS_vcbattRequestData : 7|64@0+ (1,0) [0|1.84467440737e+19] "" Vector__XXX

BO_ 1580 UDS_vcfront1Request: 8 UDS
 SG_ UDS_vcfront1RequestData : 7|64@0+ (1,0) [0|1.84467440737e+19] "" Vector__XXX

BO_ 1582 UDS_vcfront2Request: 8 UDS
 SG_ UDS_vcfront2RequestData : 7|64@0+ (1,0) [0|1.84467440737e+19] "" Vector__XXX

BO_ 1536 UDS_vcfrontRequest: 8 UDS
 SG_ UDS_vcfrontRequestData : 7|64@0+ (1,0) [0|1.84467440737e+19] "" Vector__XXX

BO_ 1570 UDS_vcleftRequest: 8 UDS
 SG_ UDS_vcleftRequestData_H : 7|32@0+ (1,0) [0|4294967295] "" Vector__XXX
 SG_ UDS_vcleftRequestData_L : 39|32@0+ (1,0) [0|4294967295] "" Vector__XXX

BO_ 1544 UDS_vcrightRequest: 8 UDS
 SG_ UDS_vcrightRequestData_H : 7|32@0+ (1,0) [0|4294967295] "" Vector__XXX
 SG_ UDS_vcrightRequestData_L : 39|32@0+ (1,0) [0|4294967295] "" Vector__XXX

BO_ 1546 UDS_vcsecRequest: 8 UDS
 SG_ UDS_vcsecRequestData : 7|64@0+ (1,0) [0|1.84467440737e+19] "" Vector__XXX

BO_TX_BU_ 2030 : TRCM;
BO_TX_BU_ 2019 : TRCM;
BO_TX_BU_ 1641 : UDS;
BO_TX_BU_ 1538 : UDS;
BO_TX_BU_ 1579 : UDS;
BO_TX_BU_ 1539 : UDS;
BO_TX_BU_ 1543 : UDS;
BO_TX_BU_ 1550 : UDS;
BO_TX_BU_ 1609 : UDS;
BO_TX_BU_ 1589 : UDS;
BO_TX_BU_ 1541 : UDS;
BO_TX_BU_ 1542 : UDS;
BO_TX_BU_ 1584 : UDS;
BO_TX_BU_ 1840 : UDS;
BO_TX_BU_ 1572 : UDS;
BO_TX_BU_ 1574 : UDS;
BO_TX_BU_ 1605 : UDS;
BO_TX_BU_ 2015 : UDS;
BO_TX_BU_ 2014 : UDS;
BO_TX_BU_ 1552 : UDS;
BO_TX_BU_ 1613 : UDS;
BO_TX_BU_ 1560 : UDS;
BO_TX_BU_ 1603 : UDS;
BO_TX_BU_ 1614 : UDS;
BO_TX_BU_ 1576 : UDS;
BO_TX_BU_ 1634 : UDS;
BO_TX_BU_ 1568 : UDS;
BO_TX_BU_ 1604 : UDS;
BO_TX_BU_ 1540 : UDS;
BO_TX_BU_ 1734 : UDS;
BO_TX_BU_ 1649 : UDS;
BO_TX_BU_ 1601 : UDS;
BO_TX_BU_ 1664 : UDS;
BO_TX_BU_ 1723 : UDS;
BO_TX_BU_ 1611 : UDS;
BO_TX_BU_ 1551 : UDS;
BO_TX_BU_ 1615 : UDS;
BO_TX_BU_ 1578 : UDS;
BO_TX_BU_ 1588 : UDS;
BO_TX_BU_ 1636 : UDS;
BO_TX_BU_ 1580 : UDS;
BO_TX_BU_ 1582 : UDS;
BO_TX_BU_ 1536 : UDS;
BO_TX_BU_ 1570 : UDS;
BO_TX_BU_ 1544 : UDS;
BO_TX_BU_ 1546 : UDS;
CM_ BO_ 2030 "TRCM ECU message: alert matrix";
CM_ SG_ 2030 TRCM_matrixIndex "TRCM ECU: matrix index";
CM_ SG_ 2030 TRCM_a001_airbagsDisabled "TRCM ECU: a001 airbags disabled";
CM_ SG_ 2030 TRCM_a002_systemDisabled "TRCM ECU: a002 system disabled";
CM_ SG_ 2030 TRCM_a003_SWAssertion "TRCM ECU: a003 SW assertion";
CM_ SG_ 2030 TRCM_a004_internalFailure "TRCM ECU: a004 internal failure";
CM_ SG_ 2030 TRCM_a005_CANTXError "TRCM ECU: a005 CANTX error";
CM_ SG_ 2030 TRCM_a006_CANTX_cyclicError "TRCM ECU: a006 CANTX cyclic error";
CM_ SG_ 2030 TRCM_a007_chassisChecksumError "TRCM ECU: a007 chassis checksum error";
CM_ SG_ 2030 TRCM_a008_chassisCounterError "TRCM ECU: a008 chassis counter error";
CM_ SG_ 2030 TRCM_a009_partyChecksumError "TRCM ECU: a009 party checksum error";
CM_ SG_ 2030 TRCM_a010_partyCounterError "TRCM ECU: a010 party counter error";
CM_ SG_ 2030 TRCM_a011_edrDataLocked "TRCM ECU: a011 edr data locked";
CM_ SG_ 2030 TRCM_a012_asm5TemperatureOutside "TRCM ECU: a012 asm5 temperature outside signal range";
CM_ SG_ 2030 TRCM_a013_AlertManagerFault "TRCM ECU: a013 alert manager fault";
CM_ SG_ 2030 TRCM_a014_asm3TemperatureOutside "TRCM ECU: a014 asm3 temperature outside signal range";
CM_ SG_ 2030 TRCM_a015_NVMMError "TRCM ECU: a015 NVMM error";
CM_ SG_ 2030 TRCM_a016_NVMMRecordError "TRCM ECU: a016 NVMM record error";
CM_ SG_ 2030 TRCM_a017_asm5TemperatureOutside "TRCM ECU: a017 asm5 temperature outside operating range";
CM_ SG_ 2030 TRCM_a018_asm3TemperatureOutside "TRCM ECU: a018 asm3 temperature outside operating range";
CM_ SG_ 2030 TRCM_a019_Task500usError "TRCM ECU: a019 task500us error";
CM_ SG_ 2030 TRCM_a020_asm3ComStatusError "TRCM ECU: a020 asm3 com status error";
CM_ SG_ 2030 TRCM_a021_TaskSchedulerError "TRCM ECU: a021 task scheduler error";
CM_ SG_ 2030 TRCM_a022_TaskInitError "TRCM ECU: a022 task init error";
CM_ SG_ 2030 TRCM_a023_asm3ArsStatusXError "TRCM ECU: a023 asm3 ars status x error";
CM_ SG_ 2030 TRCM_a024_asm3AccStatusError "TRCM ECU: a024 asm3 acc status error";
CM_ SG_ 2030 TRCM_a025_CHCANBusFaults "TRCM ECU: a025 CHCAN bus faults";
CM_ SG_ 2030 TRCM_a026_airbagAsicDiagnosticFa "TRCM ECU: a026 airbag asic diagnostic fault";
CM_ SG_ 2030 TRCM_a027_airbagAsicDeploymentDi "TRCM ECU: a027 airbag asic deployment diagnostic fault";
CM_ SG_ 2030 TRCM_a028_chassisLengthError "TRCM ECU: a028 chassis length error";
CM_ SG_ 2030 TRCM_a030_ECULogUploadRequest "TRCM ECU: a030 ECU log upload request";
CM_ SG_ 2030 TRCM_a031_UDSActive "TRCM ECU: a031 UDS active";
CM_ SG_ 2030 TRCM_a032_ScrollCreated "TRCM ECU: a032 scroll created";
CM_ SG_ 2030 TRCM_a033_HercLogCreated "TRCM ECU: a033 herc log created";
CM_ SG_ 2030 TRCM_a034_apClipTrigger "TRCM ECU: a034 ap clip trigger";
CM_ SG_ 2030 TRCM_a035_hvDisconnectCommanded "TRCM ECU: a035 hv disconnect commanded";
CM_ SG_ 2030 TRCM_a036_crashDetected "TRCM ECU: a036 crash detected";
CM_ SG_ 2030 TRCM_a037_nearDeploy "TRCM ECU: a037 near deploy";
CM_ SG_ 2030 TRCM_a038_ens1Degraded "TRCM ECU: a038 ens1 degraded";
CM_ SG_ 2030 TRCM_a039_ens2Degraded "TRCM ECU: a039 ens2 degraded";
CM_ SG_ 2030 TRCM_a040_task500usOverrunDebug "TRCM ECU: a040 task500us overrun debug";
CM_ SG_ 2030 TRCM_a041_HighCPULoad "TRCM ECU: a041 high CPU load";
CM_ SG_ 2030 TRCM_a042_HighStackUsage "TRCM ECU: a042 high stack usage";
CM_ SG_ 2030 TRCM_a043_Task1msError "TRCM ECU: a043 task1ms error";
CM_ SG_ 2030 TRCM_a044_Task10msError "TRCM ECU: a044 task10ms error";
CM_ SG_ 2030 TRCM_a045_Task100msError "TRCM ECU: a045 task100ms error";
CM_ SG_ 2030 TRCM_a046_Task1000msError "TRCM ECU: a046 task1000ms error";
CM_ SG_ 2030 TRCM_a047_vinNotLearned "TRCM ECU: a047 vin not learned";
CM_ SG_ 2030 TRCM_a048_vinMismatch "TRCM ECU: a048 vin mismatch";
CM_ SG_ 2030 TRCM_a049_nvmDebugInfo "TRCM ECU: a049 nvm debug info";
CM_ SG_ 2030 TRCM_a050_partyLengthError "TRCM ECU: a050 party length error";
CM_ SG_ 2030 TRCM_a051_systemSelfTestTimeout "TRCM ECU: a051 system self test timeout";
CM_ SG_ 2030 TRCM_a057_HVP_MIA "TRCM ECU: a057 HVP MIA";
CM_ SG_ 2030 TRCM_a058_inputRHighSyncDebug "TRCM ECU: a058 input r high sync debug";
CM_ SG_ 2030 TRCM_a059_inputResistanceHigh "TRCM ECU: a059 input resistance high";
CM_ SG_ 2030 TRCM_a060_engineeringBuild "TRCM ECU: a060 engineering build";
CM_ SG_ 2030 TRCM_a061_XCPConnected "TRCM ECU: a061 XCP connected";
CM_ SG_ 2030 TRCM_a062_XCPWasConnected "TRCM ECU: a062 XCP was connected";
CM_ SG_ 2030 TRCM_a063_SwitchFault "TRCM ECU: a063 switch fault";
CM_ SG_ 2030 TRCM_a064_busSleepReqTimeout "TRCM ECU: a064 bus sleep req timeout";
CM_ SG_ 2030 TRCM_a065_vSafingFetUnderVoltage "TRCM ECU: a065 v safing fet under voltage";
CM_ SG_ 2030 TRCM_a066_leftPowerIssue "TRCM ECU: a066 left power issue";
CM_ SG_ 2030 TRCM_a067_rightPowerIssue "TRCM ECU: a067 right power issue";
CM_ SG_ 2030 TRCM_a068_vBusCUnderVoltage "TRCM ECU: a068 v bus c under voltage";
CM_ SG_ 2030 TRCM_a069_swAppBoot "TRCM ECU: a069 sw app boot";
CM_ SG_ 2030 TRCM_a070_asm3StatusError "TRCM ECU: a070 asm3 status error";
CM_ SG_ 2030 TRCM_a071_asm3DeviceFaulted "TRCM ECU: a071 asm3 device faulted";
CM_ SG_ 2030 TRCM_a072_ais2120StatusError "TRCM ECU: a072 ais2120 status error";
CM_ SG_ 2030 TRCM_a073_ais2120DeviceFaulted "TRCM ECU: a073 ais2120 device faulted";
CM_ SG_ 2030 TRCM_a074_ais2120SelfTestXPositi "TRCM ECU: a074 ais2120 self test x positive failed";
CM_ SG_ 2030 TRCM_a075_ais2120SelfTestXNegati "TRCM ECU: a075 ais2120 self test x negative failed";
CM_ SG_ 2030 TRCM_a076_ais2120SelfTestYPositi "TRCM ECU: a076 ais2120 self test y positive failed";
CM_ SG_ 2030 TRCM_a077_ais2120SelfTestYNegati "TRCM ECU: a077 ais2120 self test y negative failed";
CM_ SG_ 2030 TRCM_a078_imuSensorSignalMonitor "TRCM ECU: a078 imu sensor signal monitor";
CM_ SG_ 2030 TRCM_a081_powerLossDetected "TRCM ECU: a081 power loss detected";
CM_ SG_ 2030 TRCM_a082_VCRIGHT_IPC_MIA "TRCM ECU: a082 VCRIGHT IPC MIA";
CM_ SG_ 2030 TRCM_a083_VCLEFT_IPC_MIA "TRCM ECU: a083 VCLEFT IPC MIA";
CM_ SG_ 2030 TRCM_a084_TPMS_MIA "TRCM ECU: a084 TPMS MIA";
CM_ SG_ 2030 TRCM_a085_CCCM_MIA "TRCM ECU: a085 CCCM MIA";
CM_ SG_ 2030 TRCM_a086_VCBATT_MIA "TRCM ECU: a086 VCBATT MIA";
CM_ SG_ 2030 TRCM_a087_DIREL_MIA "TRCM ECU: a087 DIREL MIA";
CM_ SG_ 2030 TRCM_a088_DIRER_MIA "TRCM ECU: a088 DIRER MIA";
CM_ SG_ 2030 TRCM_a089_IBST_MIA "TRCM ECU: a089 IBST MIA";
CM_ SG_ 2030 TRCM_a090_APS_MIA "TRCM ECU: a090 APS MIA";
CM_ SG_ 2030 TRCM_a091_CMPD_MIA "TRCM ECU: a091 CMPD MIA";
CM_ SG_ 2030 TRCM_a092_VCSEATD_MIA "TRCM ECU: a092 VCSEATD MIA";
CM_ SG_ 2030 TRCM_a093_VCSEATP_MIA "TRCM ECU: a093 VCSEATP MIA";
CM_ SG_ 2030 TRCM_a094_EPAS3P_MIA "TRCM ECU: a094 EPAS3 p MIA";
CM_ SG_ 2030 TRCM_a095_CHG_MIA "TRCM ECU: a095 CHG MIA";
CM_ SG_ 2030 TRCM_a096_OCS1P_MIA "TRCM ECU: a096 OCS1 p MIA";
CM_ SG_ 2030 TRCM_a097_CMP_MIA "TRCM ECU: a097 CMP MIA";
CM_ SG_ 2030 TRCM_a098_DIR_MIA "TRCM ECU: a098 DIR MIA";
CM_ SG_ 2030 TRCM_a099_PARK_MIA "TRCM ECU: a099 PARK MIA";
CM_ SG_ 2030 TRCM_a100_CANbus_MIA "TRCM ECU: a100 CA nbus MIA";
CM_ SG_ 2030 TRCM_a101_PM_MIA "TRCM ECU: a101 PM MIA";
CM_ SG_ 2030 TRCM_a102_PTC_MIA "TRCM ECU: a102 PTC MIA";
CM_ SG_ 2030 TRCM_a103_CP_MIA "TRCM ECU: a103 CP MIA";
CM_ SG_ 2030 TRCM_a104_DAS_MIA "TRCM ECU: a104 DAS MIA";
CM_ SG_ 2030 TRCM_a105_TAS_MIA "TRCM ECU: a105 TAS MIA";
CM_ SG_ 2030 TRCM_a106_PCS_MIA "TRCM ECU: a106 PCS MIA";
CM_ SG_ 2030 TRCM_a107_BMS_MIA "TRCM ECU: a107 BMS MIA";
CM_ SG_ 2030 TRCM_a108_DIF_MIA "TRCM ECU: a108 DIF MIA";
CM_ SG_ 2030 TRCM_a109_RCM_MIA "TRCM ECU: a109 RCM MIA";
CM_ SG_ 2030 TRCM_a110_GTW_MIA "TRCM ECU: a110 GTW MIA";
CM_ SG_ 2030 TRCM_a111_EPBR_MIA "TRCM ECU: a111 EPBR MIA";
CM_ SG_ 2030 TRCM_a112_EPBL_MIA "TRCM ECU: a112 EPBL MIA";
CM_ SG_ 2030 TRCM_a113_UI_MIA "TRCM ECU: a113 UI MIA";
CM_ SG_ 2030 TRCM_a114_ESP_MIA "TRCM ECU: a114 ESP MIA";
CM_ SG_ 2030 TRCM_a115_VCSEC_MIA "TRCM ECU: a115 VCSEC MIA";
CM_ SG_ 2030 TRCM_a116_VCRIGHT_MIA "TRCM ECU: a116 VCRIGHT MIA";
CM_ SG_ 2030 TRCM_a117_VCLEFT_MIA "TRCM ECU: a117 VCLEFT MIA";
CM_ SG_ 2030 TRCM_a118_VCFRONT_MIA "TRCM ECU: a118 VCFRONT MIA";
CM_ SG_ 2030 TRCM_a119_SCCM_MIA "TRCM ECU: a119 SCCM MIA";
CM_ SG_ 2030 TRCM_a120_DI_DRIVE_MIA "TRCM ECU: a120 DI DRIVE MIA";
CM_ SG_ 2030 TRCM_a121_buckleStatusFrontLeftS "TRCM ECU: a121 buckle status front left signal not okay";
CM_ SG_ 2030 TRCM_a122_buckleStatusFrontRight "TRCM ECU: a122 buckle status front right signal not okay";
CM_ SG_ 2030 TRCM_a123_buckleStatusRearLeftSi "TRCM ECU: a123 buckle status rear left signal not okay";
CM_ SG_ 2030 TRCM_a124_buckleStatusRearRightS "TRCM ECU: a124 buckle status rear right signal not okay";
CM_ SG_ 2030 TRCM_a125_occupantClassification "TRCM ECU: a125 occupant classification signal not okay";
CM_ SG_ 2030 TRCM_a126_seatTrackPositionLeftS "TRCM ECU: a126 seat track position left signal not okay";
CM_ SG_ 2030 TRCM_a127_seatTrackPositionRight "TRCM ECU: a127 seat track position right signal not okay";
CM_ SG_ 2030 TRCM_a135_asm5StatusError "TRCM ECU: a135 asm5 status error";
CM_ SG_ 2030 TRCM_a136_asm5DeviceFaulted "TRCM ECU: a136 asm5 device faulted";
CM_ SG_ 2030 TRCM_a137_ext1AsicSnoopTestFaile "TRCM ECU: a137 ext1 asic snoop test failed";
CM_ SG_ 2030 TRCM_a138_ext2AsicSnoopTestFaile "TRCM ECU: a138 ext2 asic snoop test failed";
CM_ SG_ 2030 TRCM_a145_frontCenterAccelReport "TRCM ECU: a145 front center accel reported error";
CM_ SG_ 2030 TRCM_a146_frontCenterAccelGenera "TRCM ECU: a146 front center accel general issue";
CM_ SG_ 2030 TRCM_a147_frontCenterAccelElectr "TRCM ECU: a147 front center accel electrical issue";
CM_ SG_ 2030 TRCM_a148_frontCenterAccelConfig "TRCM ECU: a148 front center accel config error";
CM_ SG_ 2030 TRCM_a149_frontCenterAccelSignal "TRCM ECU: a149 front center accel signal monitor";
CM_ SG_ 2030 TRCM_a150_frontLeftAccelReported "TRCM ECU: a150 front left accel reported error";
CM_ SG_ 2030 TRCM_a151_frontLeftAccelGeneralI "TRCM ECU: a151 front left accel general issue";
CM_ SG_ 2030 TRCM_a152_frontLeftAccelElectric "TRCM ECU: a152 front left accel electrical issue";
CM_ SG_ 2030 TRCM_a153_frontLeftAccelConfigEr "TRCM ECU: a153 front left accel config error";
CM_ SG_ 2030 TRCM_a154_frontLeftAccelSignalMo "TRCM ECU: a154 front left accel signal monitor";
CM_ SG_ 2030 TRCM_a155_frontLeftDoorPressureR "TRCM ECU: a155 front left door pressure reported error";
CM_ SG_ 2030 TRCM_a156_frontLeftDoorPressureG "TRCM ECU: a156 front left door pressure general issue";
CM_ SG_ 2030 TRCM_a157_frontLeftDoorPressureE "TRCM ECU: a157 front left door pressure electrical issue";
CM_ SG_ 2030 TRCM_a158_frontLeftDoorPressureC "TRCM ECU: a158 front left door pressure config error";
CM_ SG_ 2030 TRCM_a159_frontLeftDoorPressureS "TRCM ECU: a159 front left door pressure signal monitor";
CM_ SG_ 2030 TRCM_a160_frontRightAccelReporte "TRCM ECU: a160 front right accel reported error";
CM_ SG_ 2030 TRCM_a161_frontRightAccelGeneral "TRCM ECU: a161 front right accel general issue";
CM_ SG_ 2030 TRCM_a162_frontRightAccelElectri "TRCM ECU: a162 front right accel electrical issue";
CM_ SG_ 2030 TRCM_a163_frontRightAccelConfigE "TRCM ECU: a163 front right accel config error";
CM_ SG_ 2030 TRCM_a164_frontRightAccelSignalM "TRCM ECU: a164 front right accel signal monitor";
CM_ SG_ 2030 TRCM_a165_frontRightDoorPressure "TRCM ECU: a165 front right door pressure reported error";
CM_ SG_ 2030 TRCM_a166_frontRightDoorPressure "TRCM ECU: a166 front right door pressure general issue";
CM_ SG_ 2030 TRCM_a167_frontRightDoorPressure "TRCM ECU: a167 front right door pressure electrical issue";
CM_ SG_ 2030 TRCM_a168_frontRightDoorPressure "TRCM ECU: a168 front right door pressure config error";
CM_ SG_ 2030 TRCM_a169_frontRightDoorPressure "TRCM ECU: a169 front right door pressure signal monitor";
CM_ SG_ 2030 TRCM_a170_leftBPillarAccelReport "TRCM ECU: a170 left b pillar accel reported error";
CM_ SG_ 2030 TRCM_a171_leftBPillarAccelGenera "TRCM ECU: a171 left b pillar accel general issue";
CM_ SG_ 2030 TRCM_a172_leftBPillarAccelElectr "TRCM ECU: a172 left b pillar accel electrical issue";
CM_ SG_ 2030 TRCM_a173_leftBPillarAccelConfig "TRCM ECU: a173 left b pillar accel config error";
CM_ SG_ 2030 TRCM_a174_leftBPillarAccelSignal "TRCM ECU: a174 left b pillar accel signal monitor";
CM_ SG_ 2030 TRCM_a175_leftCPillarAccelReport "TRCM ECU: a175 left c pillar accel reported error";
CM_ SG_ 2030 TRCM_a176_leftCPillarAccelGenera "TRCM ECU: a176 left c pillar accel general issue";
CM_ SG_ 2030 TRCM_a177_leftCPillarAccelElectr "TRCM ECU: a177 left c pillar accel electrical issue";
CM_ SG_ 2030 TRCM_a178_leftCPillarAccelConfig "TRCM ECU: a178 left c pillar accel config error";
CM_ SG_ 2030 TRCM_a179_leftCPillarAccelSignal "TRCM ECU: a179 left c pillar accel signal monitor";
CM_ SG_ 2030 TRCM_a190_rearLeftDoorPressureRe "TRCM ECU: a190 rear left door pressure reported error";
CM_ SG_ 2030 TRCM_a191_rearLeftDoorPressureGe "TRCM ECU: a191 rear left door pressure general issue";
CM_ SG_ 2030 TRCM_a192_rearLeftDoorPressureEl "TRCM ECU: a192 rear left door pressure electrical issue";
CM_ SG_ 2030 TRCM_a193_rearLeftDoorPressureCo "TRCM ECU: a193 rear left door pressure config error";
CM_ SG_ 2030 TRCM_a194_rearLeftDoorPressureSi "TRCM ECU: a194 rear left door pressure signal monitor";
CM_ SG_ 2030 TRCM_a195_rearRightDoorPressureR "TRCM ECU: a195 rear right door pressure reported error";
CM_ SG_ 2030 TRCM_a196_rearRightDoorPressureG "TRCM ECU: a196 rear right door pressure general issue";
CM_ SG_ 2030 TRCM_a197_rearRightDoorPressureE "TRCM ECU: a197 rear right door pressure electrical issue";
CM_ SG_ 2030 TRCM_a198_rearRightDoorPressureC "TRCM ECU: a198 rear right door pressure config error";
CM_ SG_ 2030 TRCM_a199_rearRightDoorPressureS "TRCM ECU: a199 rear right door pressure signal monitor";
CM_ SG_ 2030 TRCM_a200_rightBPillarAccelRepor "TRCM ECU: a200 right b pillar accel reported error";
CM_ SG_ 2030 TRCM_a201_rightBPillarAccelGener "TRCM ECU: a201 right b pillar accel general issue";
CM_ SG_ 2030 TRCM_a202_rightBPillarAccelElect "TRCM ECU: a202 right b pillar accel electrical issue";
CM_ SG_ 2030 TRCM_a203_rightBPillarAccelConfi "TRCM ECU: a203 right b pillar accel config error";
CM_ SG_ 2030 TRCM_a204_rightBPillarAccelSigna "TRCM ECU: a204 right b pillar accel signal monitor";
CM_ SG_ 2030 TRCM_a205_rightCPillarAccelRepor "TRCM ECU: a205 right c pillar accel reported error";
CM_ SG_ 2030 TRCM_a206_rightCPillarAccelGener "TRCM ECU: a206 right c pillar accel general issue";
CM_ SG_ 2030 TRCM_a207_rightCPillarAccelElect "TRCM ECU: a207 right c pillar accel electrical issue";
CM_ SG_ 2030 TRCM_a208_rightCPillarAccelConfi "TRCM ECU: a208 right c pillar accel config error";
CM_ SG_ 2030 TRCM_a209_rightCPillarAccelSigna "TRCM ECU: a209 right c pillar accel signal monitor";
CM_ SG_ 2030 TRCM_a272_asm5ComStatusError "TRCM ECU: a272 asm5 com status error";
CM_ SG_ 2030 TRCM_a273_asm5ArsStatusXError "TRCM ECU: a273 asm5 ars status x error";
CM_ SG_ 2030 TRCM_a274_asm5ArsStatusZError "TRCM ECU: a274 asm5 ars status z error";
CM_ SG_ 2030 TRCM_a275_asm5AccStatusError "TRCM ECU: a275 asm5 acc status error";
CM_ SG_ 2030 TRCM_a276_watchdogStatus "TRCM ECU: a276 watchdog status";
CM_ SG_ 2030 TRCM_a278_safingEngine0Armed "TRCM ECU: a278 safing engine0 armed";
CM_ SG_ 2030 TRCM_a279_safingEngine1Armed "TRCM ECU: a279 safing engine1 armed";
CM_ SG_ 2030 TRCM_a280_safingEngine2Armed "TRCM ECU: a280 safing engine2 armed";
CM_ SG_ 2030 TRCM_a281_safingEngine3Armed "TRCM ECU: a281 safing engine3 armed";
CM_ SG_ 2030 TRCM_a282_safingEngine4Armed "TRCM ECU: a282 safing engine4 armed";
CM_ SG_ 2030 TRCM_a283_safingEngine5Armed "TRCM ECU: a283 safing engine5 armed";
CM_ SG_ 2030 TRCM_a284_safingEngine6Armed "TRCM ECU: a284 safing engine6 armed";
CM_ SG_ 2030 TRCM_a285_safingEngine7Armed "TRCM ECU: a285 safing engine7 armed";
CM_ SG_ 2030 TRCM_a286_safingEngine8Armed "TRCM ECU: a286 safing engine8 armed";
CM_ SG_ 2030 TRCM_a287_safingEngine9Armed "TRCM ECU: a287 safing engine9 armed";
CM_ SG_ 2030 TRCM_a288_safingEngine10Armed "TRCM ECU: a288 safing engine10 armed";
CM_ SG_ 2030 TRCM_a289_safingEngine11Armed "TRCM ECU: a289 safing engine11 armed";
CM_ SG_ 2030 TRCM_a290_safingEngine12Armed "TRCM ECU: a290 safing engine12 armed";
CM_ SG_ 2030 TRCM_a291_safingEngine13Armed "TRCM ECU: a291 safing engine13 armed";
CM_ SG_ 2030 TRCM_a292_safingEngine14Armed "TRCM ECU: a292 safing engine14 armed";
CM_ SG_ 2030 TRCM_a293_safingEngine15Armed "TRCM ECU: a293 safing engine15 armed";
CM_ SG_ 2030 TRCM_a294_safingEngine16Armed "TRCM ECU: a294 safing engine16 armed";
CM_ SG_ 2030 TRCM_a295_safingEngine17Armed "TRCM ECU: a295 safing engine17 armed";
CM_ SG_ 2030 TRCM_a296_safingEngine18Armed "TRCM ECU: a296 safing engine18 armed";
CM_ SG_ 2030 TRCM_a297_safingEngine19Armed "TRCM ECU: a297 safing engine19 armed";
CM_ SG_ 2030 TRCM_a298_safingEngine20Armed "TRCM ECU: a298 safing engine20 armed";
CM_ SG_ 2030 TRCM_a299_safingEngine21Armed "TRCM ECU: a299 safing engine21 armed";
CM_ SG_ 2030 TRCM_a300_driverAirbagStage1Supp "TRCM ECU: a300 driver airbag stage1 suppressed";
CM_ SG_ 2030 TRCM_a301_passengerAirbagStage1S "TRCM ECU: a301 passenger airbag stage1 suppressed";
CM_ SG_ 2030 TRCM_a302_driverAirbagStage2Supp "TRCM ECU: a302 driver airbag stage2 suppressed";
CM_ SG_ 2030 TRCM_a303_driverAirbagActiveVent "TRCM ECU: a303 driver airbag active vent suppressed";
CM_ SG_ 2030 TRCM_a304_passengerAirbagStage2S "TRCM ECU: a304 passenger airbag stage2 suppressed";
CM_ SG_ 2030 TRCM_a305_passengerAirbagActiveV "TRCM ECU: a305 passenger airbag active vent suppressed";
CM_ SG_ 2030 TRCM_a306_inboardSeatAirbagSuppr "TRCM ECU: a306 inboard seat airbag suppressed";
CM_ SG_ 2030 TRCM_a308_kneeAirbagLeftSuppress "TRCM ECU: a308 knee airbag left suppressed";
CM_ SG_ 2030 TRCM_a309_kneeAirbagRightSuppres "TRCM ECU: a309 knee airbag right suppressed";
CM_ SG_ 2030 TRCM_a310_curtainAirbagLeftSuppr "TRCM ECU: a310 curtain airbag left suppressed";
CM_ SG_ 2030 TRCM_a311_curtainAirbagRightSupp "TRCM ECU: a311 curtain airbag right suppressed";
CM_ SG_ 2030 TRCM_a312_seatbeltLoadLimiterFro "TRCM ECU: a312 seatbelt load limiter front left suppressed";
CM_ SG_ 2030 TRCM_a313_seatbeltLoadLimiterFro "TRCM ECU: a313 seatbelt load limiter front right suppressed";
CM_ SG_ 2030 TRCM_a314_seatbeltShoulderPreten "TRCM ECU: a314 seatbelt shoulder pretensioner front left suppressed";
CM_ SG_ 2030 TRCM_a315_seatbeltShoulderPreten "TRCM ECU: a315 seatbelt shoulder pretensioner front right suppressed";
CM_ SG_ 2030 TRCM_a316_seatbeltLapPretensione "TRCM ECU: a316 seatbelt lap pretensioner front left suppressed";
CM_ SG_ 2030 TRCM_a317_seatbeltLapPretensione "TRCM ECU: a317 seatbelt lap pretensioner front right suppressed";
CM_ SG_ 2030 TRCM_a318_outboardSeatAirbagLeft "TRCM ECU: a318 outboard seat airbag left suppressed";
CM_ SG_ 2030 TRCM_a319_outboardSeatAirbagRigh "TRCM ECU: a319 outboard seat airbag right suppressed";
CM_ SG_ 2030 TRCM_a320_hoodLifterLeftSuppress "TRCM ECU: a320 hood lifter left suppressed";
CM_ SG_ 2030 TRCM_a321_hoodLifterRightSuppres "TRCM ECU: a321 hood lifter right suppressed";
CM_ SG_ 2030 TRCM_a322_seatbeltShoulderPreten "TRCM ECU: a322 seatbelt shoulder pretensioner rear left suppressed";
CM_ SG_ 2030 TRCM_a323_seatbeltShoulderPreten "TRCM ECU: a323 seatbelt shoulder pretensioner rear right suppressed";
CM_ SG_ 2030 TRCM_a332_driverAirbagStage1Depl "TRCM ECU: a332 driver airbag stage1 deployed";
CM_ SG_ 2030 TRCM_a333_passengerAirbagStage1D "TRCM ECU: a333 passenger airbag stage1 deployed";
CM_ SG_ 2030 TRCM_a334_driverAirbagStage2Depl "TRCM ECU: a334 driver airbag stage2 deployed";
CM_ SG_ 2030 TRCM_a335_driverAirbagActiveVent "TRCM ECU: a335 driver airbag active vent deployed";
CM_ SG_ 2030 TRCM_a336_passengerAirbagStage2D "TRCM ECU: a336 passenger airbag stage2 deployed";
CM_ SG_ 2030 TRCM_a337_passengerAirbagActiveV "TRCM ECU: a337 passenger airbag active vent deployed";
CM_ SG_ 2030 TRCM_a338_inboardSeatAirbagDeplo "TRCM ECU: a338 inboard seat airbag deployed";
CM_ SG_ 2030 TRCM_a340_kneeAirbagLeftDeployed "TRCM ECU: a340 knee airbag left deployed";
CM_ SG_ 2030 TRCM_a341_kneeAirbagRightDeploye "TRCM ECU: a341 knee airbag right deployed";
CM_ SG_ 2030 TRCM_a342_curtainAirbagLeftDeplo "TRCM ECU: a342 curtain airbag left deployed";
CM_ SG_ 2030 TRCM_a343_curtainAirbagRightDepl "TRCM ECU: a343 curtain airbag right deployed";
CM_ SG_ 2030 TRCM_a344_seatbeltLoadLimiterFro "TRCM ECU: a344 seatbelt load limiter front left deployed";
CM_ SG_ 2030 TRCM_a345_seatbeltLoadLimiterFro "TRCM ECU: a345 seatbelt load limiter front right deployed";
CM_ SG_ 2030 TRCM_a346_seatbeltShoulderPreten "TRCM ECU: a346 seatbelt shoulder pretensioner front left deployed";
CM_ SG_ 2030 TRCM_a347_seatbeltShoulderPreten "TRCM ECU: a347 seatbelt shoulder pretensioner front right deployed";
CM_ SG_ 2030 TRCM_a348_seatbeltLapPretensione "TRCM ECU: a348 seatbelt lap pretensioner front left deployed";
CM_ SG_ 2030 TRCM_a349_seatbeltLapPretensione "TRCM ECU: a349 seatbelt lap pretensioner front right deployed";
CM_ SG_ 2030 TRCM_a350_outboardSeatAirbagLeft "TRCM ECU: a350 outboard seat airbag left deployed";
CM_ SG_ 2030 TRCM_a351_outboardSeatAirbagRigh "TRCM ECU: a351 outboard seat airbag right deployed";
CM_ SG_ 2030 TRCM_a352_hoodLifterLeftDeployed "TRCM ECU: a352 hood lifter left deployed";
CM_ SG_ 2030 TRCM_a353_hoodLifterRightDeploye "TRCM ECU: a353 hood lifter right deployed";
CM_ SG_ 2030 TRCM_a354_seatbeltShoulderPreten "TRCM ECU: a354 seatbelt shoulder pretensioner rear left deployed";
CM_ SG_ 2030 TRCM_a355_seatbeltShoulderPreten "TRCM ECU: a355 seatbelt shoulder pretensioner rear right deployed";
CM_ SG_ 2030 TRCM_a364_safingEngine0NoValidDa "TRCM ECU: a364 safing engine0 no valid data";
CM_ SG_ 2030 TRCM_a365_safingEngine1NoValidDa "TRCM ECU: a365 safing engine1 no valid data";
CM_ SG_ 2030 TRCM_a366_safingEngine2NoValidDa "TRCM ECU: a366 safing engine2 no valid data";
CM_ SG_ 2030 TRCM_a367_safingEngine3NoValidDa "TRCM ECU: a367 safing engine3 no valid data";
CM_ SG_ 2030 TRCM_a368_safingEngine4NoValidDa "TRCM ECU: a368 safing engine4 no valid data";
CM_ SG_ 2030 TRCM_a369_safingEngine5NoValidDa "TRCM ECU: a369 safing engine5 no valid data";
CM_ SG_ 2030 TRCM_a370_safingEngine6NoValidDa "TRCM ECU: a370 safing engine6 no valid data";
CM_ SG_ 2030 TRCM_a371_safingEngine7NoValidDa "TRCM ECU: a371 safing engine7 no valid data";
CM_ SG_ 2030 TRCM_a372_safingEngine8NoValidDa "TRCM ECU: a372 safing engine8 no valid data";
CM_ SG_ 2030 TRCM_a373_safingEngine9NoValidDa "TRCM ECU: a373 safing engine9 no valid data";
CM_ SG_ 2030 TRCM_a374_safingEngine10NoValidD "TRCM ECU: a374 safing engine10 no valid data";
CM_ SG_ 2030 TRCM_a375_safingEngine11NoValidD "TRCM ECU: a375 safing engine11 no valid data";
CM_ SG_ 2030 TRCM_a376_safingEngine12NoValidD "TRCM ECU: a376 safing engine12 no valid data";
CM_ SG_ 2030 TRCM_a377_safingEngine13NoValidD "TRCM ECU: a377 safing engine13 no valid data";
CM_ SG_ 2030 TRCM_a378_safingEngine14NoValidD "TRCM ECU: a378 safing engine14 no valid data";
CM_ SG_ 2030 TRCM_a379_safingEngine15NoValidD "TRCM ECU: a379 safing engine15 no valid data";
CM_ SG_ 2030 TRCM_a380_safingEngine16NoValidD "TRCM ECU: a380 safing engine16 no valid data";
CM_ SG_ 2030 TRCM_a381_safingEngine17NoValidD "TRCM ECU: a381 safing engine17 no valid data";
CM_ SG_ 2030 TRCM_a382_safingEngine18NoValidD "TRCM ECU: a382 safing engine18 no valid data";
CM_ SG_ 2030 TRCM_a383_safingEngine19NoValidD "TRCM ECU: a383 safing engine19 no valid data";
CM_ SG_ 2030 TRCM_a384_safingEngine20NoValidD "TRCM ECU: a384 safing engine20 no valid data";
CM_ SG_ 2030 TRCM_a385_safingEngine21NoValidD "TRCM ECU: a385 safing engine21 no valid data";
CM_ SG_ 2030 TRCM_a387_primaryAsicResetSource "TRCM ECU: a387 primary asic reset source";
CM_ SG_ 2030 TRCM_a388_cpuLoadHigh "TRCM ECU: a388 cpu load high";
CM_ SG_ 2030 TRCM_a389_asicPwrStatusError "TRCM ECU: a389 asic pwr status error";
CM_ SG_ 2030 TRCM_a390_systemAsicClockOrOpera "TRCM ECU: a390 system asic clock or operating state error";
CM_ SG_ 2030 TRCM_a391_extAsic1ClockOrOperati "TRCM ECU: a391 ext asic1 clock or operating state error";
CM_ SG_ 2030 TRCM_a392_extAsic2ClockOrOperati "TRCM ECU: a392 ext asic2 clock or operating state error";
CM_ SG_ 2030 TRCM_a393_depAdcConvertRatioErro "TRCM ECU: a393 dep adc convert ratio error";
CM_ SG_ 2030 TRCM_a394_gspiGlobalStatusWordEr "TRCM ECU: a394 gspi global status word error";
CM_ SG_ 2030 TRCM_a395_imuUncalibrated "TRCM ECU: a395 imu uncalibrated";
CM_ SG_ 2030 TRCM_a396_spiCommunicationProgra "TRCM ECU: a396 spi communication program error";
CM_ SG_ 2030 TRCM_a397_safingMonitorError "TRCM ECU: a397 safing monitor error";
CM_ SG_ 2030 TRCM_a398_asicNvmReprogrammed "TRCM ECU: a398 asic nvm reprogrammed";
CM_ SG_ 2030 TRCM_a399_imuCalibrationComplete "TRCM ECU: a399 imu calibration complete";
CM_ SG_ 2030 TRCM_a400_driverAirbagStage1Issu "TRCM ECU: a400 driver airbag stage1 issue";
CM_ SG_ 2030 TRCM_a401_passengerAirbagStage1I "TRCM ECU: a401 passenger airbag stage1 issue";
CM_ SG_ 2030 TRCM_a402_driverAirbagStage2Issu "TRCM ECU: a402 driver airbag stage2 issue";
CM_ SG_ 2030 TRCM_a403_driverAirbagActiveVent "TRCM ECU: a403 driver airbag active vent issue";
CM_ SG_ 2030 TRCM_a404_passengerAirbagStage2I "TRCM ECU: a404 passenger airbag stage2 issue";
CM_ SG_ 2030 TRCM_a405_passengerAirbagActiveV "TRCM ECU: a405 passenger airbag active vent issue";
CM_ SG_ 2030 TRCM_a406_inboardSeatAirbagIssue "TRCM ECU: a406 inboard seat airbag issue";
CM_ SG_ 2030 TRCM_a408_kneeAirbagLeftIssue "TRCM ECU: a408 knee airbag left issue";
CM_ SG_ 2030 TRCM_a409_kneeAirbagRightIssue "TRCM ECU: a409 knee airbag right issue";
CM_ SG_ 2030 TRCM_a410_curtainAirbagLeftIssue "TRCM ECU: a410 curtain airbag left issue";
CM_ SG_ 2030 TRCM_a411_curtainAirbagRightIssu "TRCM ECU: a411 curtain airbag right issue";
CM_ SG_ 2030 TRCM_a412_seatbeltLoadLimiterFro "TRCM ECU: a412 seatbelt load limiter front left issue";
CM_ SG_ 2030 TRCM_a413_seatbeltLoadLimiterFro "TRCM ECU: a413 seatbelt load limiter front right issue";
CM_ SG_ 2030 TRCM_a414_seatbeltShoulderPreten "TRCM ECU: a414 seatbelt shoulder pretensioner front left issue";
CM_ SG_ 2030 TRCM_a415_seatbeltShoulderPreten "TRCM ECU: a415 seatbelt shoulder pretensioner front right issue";
CM_ SG_ 2030 TRCM_a416_seatbeltLapPretensione "TRCM ECU: a416 seatbelt lap pretensioner front left issue";
CM_ SG_ 2030 TRCM_a417_seatbeltLapPretensione "TRCM ECU: a417 seatbelt lap pretensioner front right issue";
CM_ SG_ 2030 TRCM_a418_outboardSeatAirbagLeft "TRCM ECU: a418 outboard seat airbag left issue";
CM_ SG_ 2030 TRCM_a419_outboardSeatAirbagRigh "TRCM ECU: a419 outboard seat airbag right issue";
CM_ SG_ 2030 TRCM_a420_hoodLifterLeftIssue "TRCM ECU: a420 hood lifter left issue";
CM_ SG_ 2030 TRCM_a421_hoodLifterRightIssue "TRCM ECU: a421 hood lifter right issue";
CM_ SG_ 2030 TRCM_a422_seatbeltShoulderPreten "TRCM ECU: a422 seatbelt shoulder pretensioner rear left issue";
CM_ SG_ 2030 TRCM_a423_seatbeltShoulderPreten "TRCM ECU: a423 seatbelt shoulder pretensioner rear right issue";
CM_ SG_ 2030 TRCM_a432_driverAirbagStage1Conf "TRCM ECU: a432 driver airbag stage1 config error";
CM_ SG_ 2030 TRCM_a433_passengerAirbagStage1C "TRCM ECU: a433 passenger airbag stage1 config error";
CM_ SG_ 2030 TRCM_a434_driverAirbagStage2Conf "TRCM ECU: a434 driver airbag stage2 config error";
CM_ SG_ 2030 TRCM_a435_driverAirbagActiveVent "TRCM ECU: a435 driver airbag active vent config error";
CM_ SG_ 2030 TRCM_a436_passengerAirbagStage2C "TRCM ECU: a436 passenger airbag stage2 config error";
CM_ SG_ 2030 TRCM_a437_passengerAirbagActiveV "TRCM ECU: a437 passenger airbag active vent config error";
CM_ SG_ 2030 TRCM_a438_inboardSeatAirbagConfi "TRCM ECU: a438 inboard seat airbag config error";
CM_ SG_ 2030 TRCM_a440_kneeAirbagLeftConfigEr "TRCM ECU: a440 knee airbag left config error";
CM_ SG_ 2030 TRCM_a441_kneeAirbagRightConfigE "TRCM ECU: a441 knee airbag right config error";
CM_ SG_ 2030 TRCM_a442_curtainAirbagLeftConfi "TRCM ECU: a442 curtain airbag left config error";
CM_ SG_ 2030 TRCM_a443_curtainAirbagRightConf "TRCM ECU: a443 curtain airbag right config error";
CM_ SG_ 2030 TRCM_a444_seatbeltLoadLimiterFro "TRCM ECU: a444 seatbelt load limiter front left config error";
CM_ SG_ 2030 TRCM_a445_seatbeltLoadLimiterFro "TRCM ECU: a445 seatbelt load limiter front right config error";
CM_ SG_ 2030 TRCM_a446_seatbeltShoulderPreten "TRCM ECU: a446 seatbelt shoulder pretensioner front left config error";
CM_ SG_ 2030 TRCM_a447_seatbeltShoulderPreten "TRCM ECU: a447 seatbelt shoulder pretensioner front right config error";
CM_ SG_ 2030 TRCM_a448_seatbeltLapPretensione "TRCM ECU: a448 seatbelt lap pretensioner front left config error";
CM_ SG_ 2030 TRCM_a449_seatbeltLapPretensione "TRCM ECU: a449 seatbelt lap pretensioner front right config error";
CM_ SG_ 2030 TRCM_a450_outboardSeatAirbagLeft "TRCM ECU: a450 outboard seat airbag left config error";
CM_ SG_ 2030 TRCM_a451_outboardSeatAirbagRigh "TRCM ECU: a451 outboard seat airbag right config error";
CM_ SG_ 2030 TRCM_a452_hoodLifterLeftConfigEr "TRCM ECU: a452 hood lifter left config error";
CM_ SG_ 2030 TRCM_a453_hoodLifterRightConfigE "TRCM ECU: a453 hood lifter right config error";
CM_ SG_ 2030 TRCM_a454_seatbeltShoulderPreten "TRCM ECU: a454 seatbelt shoulder pretensioner rear left config error";
CM_ SG_ 2030 TRCM_a455_seatbeltShoulderPreten "TRCM ECU: a455 seatbelt shoulder pretensioner rear right config error";
CM_ SG_ 2030 TRCM_a544_erCapDiagnosticsFailed "TRCM ECU: a544 er cap diagnostics failed";
CM_ SG_ 2030 TRCM_a545_erCapBelowAutarkyThres "TRCM ECU: a545 er cap below autarky threshold";
CM_ SG_ 2030 TRCM_a546_sensorValuesFaultedByS "TRCM ECU: a546 sensor values faulted by smart";
CM_ SG_ 2030 TRCM_a550_AlgoWake_RCM_WAKE_FRON "TRCM ECU: a550 algo wake RCM WAKE FRONT";
CM_ SG_ 2030 TRCM_a551_AlgoWake_RCM_WAKE_REAR "TRCM ECU: a551 algo wake RCM WAKE REAR";
CM_ SG_ 2030 TRCM_a552_AlgoWake_RCM_WAKE_LEFT "TRCM ECU: a552 algo wake RCM WAKE LEFT";
CM_ SG_ 2030 TRCM_a553_AlgoWake_RCM_WAKE_RIGH "TRCM ECU: a553 algo wake RCM WAKE RIGHT";
CM_ SG_ 2030 TRCM_a554_AlgoWake_PAS_LH_PLAUSI "TRCM ECU: a554 algo wake PAS LH PLAUSI FRONT";
CM_ SG_ 2030 TRCM_a555_AlgoWake_PAS_LH_PLAUSI "TRCM ECU: a555 algo wake PAS LH PLAUSI REAR";
CM_ SG_ 2030 TRCM_a557_AlgoWake_PAS_RH_PLAUSI "TRCM ECU: a557 algo wake PAS RH PLAUSI FRONT";
CM_ SG_ 2030 TRCM_a558_AlgoWake_PAS_RH_PLAUSI "TRCM ECU: a558 algo wake PAS RH PLAUSI REAR";
CM_ SG_ 2030 TRCM_a560_AlgoWake_RCM_WAKE_ROLL "TRCM ECU: a560 algo wake RCM WAKE ROLL LEFT";
CM_ SG_ 2030 TRCM_a561_AlgoWake_RCM_WAKE_ROLL "TRCM ECU: a561 algo wake RCM WAKE ROLL RIGHT";
CM_ SG_ 2030 TRCM_a562_AlgoWake_RCM_AWAKE_FRO "TRCM ECU: a562 algo wake RCM AWAKE FRONT";
CM_ SG_ 2030 TRCM_a563_AlgoWake_RCM_AWAKE_REA "TRCM ECU: a563 algo wake RCM AWAKE REAR";
CM_ SG_ 2030 TRCM_a564_AlgoWake_RCM_AWAKE_LEF "TRCM ECU: a564 algo wake RCM AWAKE LEFT";
CM_ SG_ 2030 TRCM_a565_AlgoWake_RCM_AWAKE_RIG "TRCM ECU: a565 algo wake RCM AWAKE RIGHT";
CM_ SG_ 2030 TRCM_a566_AlgoWake_RCM_AWAKE_ROL "TRCM ECU: a566 algo wake RCM AWAKE ROLL";
CM_ SG_ 2030 TRCM_a567_AlgoWake_RCM_AWAKE_X "TRCM ECU: a567 algo wake RCM AWAKE x";
CM_ SG_ 2030 TRCM_a568_AlgoWake_RCM_AWAKE_Y "TRCM ECU: a568 algo wake RCM AWAKE y";
CM_ SG_ 2030 TRCM_a569_AlgoWake_PAS_WAKE_LEFT "TRCM ECU: a569 algo wake PAS WAKE LEFT";
CM_ SG_ 2030 TRCM_a570_AlgoWake_PAS_WAKE_RIGH "TRCM ECU: a570 algo wake PAS WAKE RIGHT";
CM_ SG_ 2030 TRCM_a576_AlgoWake_IMPACT_FINISH "TRCM ECU: a576 algo wake IMPACT FINISH x";
CM_ SG_ 2030 TRCM_a577_AlgoWake_IMPACT_FINISH "TRCM ECU: a577 algo wake IMPACT FINISH y";
CM_ SG_ 2030 TRCM_a578_AlgoWake_IMPACT_FINISH "TRCM ECU: a578 algo wake IMPACT FINISH ROLL";
CM_ SG_ 2030 TRCM_a579_AlgoWake_RCM_ENABLED_X "TRCM ECU: a579 algo wake RCM ENABLED x";
CM_ SG_ 2030 TRCM_a580_AlgoWake_RCM_ENABLED_Y "TRCM ECU: a580 algo wake RCM ENABLED y";
CM_ SG_ 2030 TRCM_a581_AlgoWake_RCM_ENABLED_R "TRCM ECU: a581 algo wake RCM ENABLED ROLL";
CM_ SG_ 2030 TRCM_a582_AlgoWake_RCM_AWAKE "TRCM ECU: a582 algo wake RCM AWAKE";
CM_ SG_ 2030 TRCM_a588_yawRateOffsetPosLimit "TRCM ECU: a588 yaw rate offset pos limit";
CM_ SG_ 2030 TRCM_a589_yawRateOffsetNegLimit "TRCM ECU: a589 yaw rate offset neg limit";
CM_ SG_ 2030 TRCM_a590_pitchRateOffsetPosLimi "TRCM ECU: a590 pitch rate offset pos limit";
CM_ SG_ 2030 TRCM_a591_pitchRateOffsetNegLimi "TRCM ECU: a591 pitch rate offset neg limit";
CM_ SG_ 2030 TRCM_a592_rollRateOffsetPosLimit "TRCM ECU: a592 roll rate offset pos limit";
CM_ SG_ 2030 TRCM_a593_rollRateOffsetNegLimit "TRCM ECU: a593 roll rate offset neg limit";
CM_ SG_ 2030 TRCM_a594_longitudinalAccelOffse "TRCM ECU: a594 longitudinal accel offset pos limit";
CM_ SG_ 2030 TRCM_a595_longitudinalAccelOffse "TRCM ECU: a595 longitudinal accel offset neg limit";
CM_ SG_ 2030 TRCM_a596_lateralAccelOffsetPosL "TRCM ECU: a596 lateral accel offset pos limit";
CM_ SG_ 2030 TRCM_a597_lateralAccelOffsetNegL "TRCM ECU: a597 lateral accel offset neg limit";
CM_ SG_ 2030 TRCM_a598_verticalAccelOffsetPos "TRCM ECU: a598 vertical accel offset pos limit";
CM_ SG_ 2030 TRCM_a599_verticalAccelOffsetNeg "TRCM ECU: a599 vertical accel offset neg limit";
CM_ SG_ 2030 TRCM_a600_airbagAsicStartupFailu "TRCM ECU: a600 airbag asic startup failure";
CM_ SG_ 2030 TRCM_a601_loop0AsicStartupDiagno "TRCM ECU: a601 loop0 asic startup diagnostic failure";
CM_ SG_ 2030 TRCM_a602_loop1AsicStartupDiagno "TRCM ECU: a602 loop1 asic startup diagnostic failure";
CM_ SG_ 2030 TRCM_a603_loop2AsicStartupDiagno "TRCM ECU: a603 loop2 asic startup diagnostic failure";
CM_ SG_ 2030 TRCM_a604_loop3AsicStartupDiagno "TRCM ECU: a604 loop3 asic startup diagnostic failure";
CM_ SG_ 2030 TRCM_a605_loop4AsicStartupDiagno "TRCM ECU: a605 loop4 asic startup diagnostic failure";
CM_ SG_ 2030 TRCM_a606_loop5AsicStartupDiagno "TRCM ECU: a606 loop5 asic startup diagnostic failure";
CM_ SG_ 2030 TRCM_a607_loop6AsicStartupDiagno "TRCM ECU: a607 loop6 asic startup diagnostic failure";
CM_ SG_ 2030 TRCM_a608_loop7AsicStartupDiagno "TRCM ECU: a608 loop7 asic startup diagnostic failure";
CM_ SG_ 2030 TRCM_a609_loop8AsicStartupDiagno "TRCM ECU: a609 loop8 asic startup diagnostic failure";
CM_ SG_ 2030 TRCM_a610_loop9AsicStartupDiagno "TRCM ECU: a610 loop9 asic startup diagnostic failure";
CM_ SG_ 2030 TRCM_a611_loop10AsicStartupDiagn "TRCM ECU: a611 loop10 asic startup diagnostic failure";
CM_ SG_ 2030 TRCM_a612_loop11AsicStartupDiagn "TRCM ECU: a612 loop11 asic startup diagnostic failure";
CM_ SG_ 2030 TRCM_a613_loop12AsicStartupDiagn "TRCM ECU: a613 loop12 asic startup diagnostic failure";
CM_ SG_ 2030 TRCM_a614_loop13AsicStartupDiagn "TRCM ECU: a614 loop13 asic startup diagnostic failure";
CM_ SG_ 2030 TRCM_a615_loop14AsicStartupDiagn "TRCM ECU: a615 loop14 asic startup diagnostic failure";
CM_ SG_ 2030 TRCM_a616_loop15AsicStartupDiagn "TRCM ECU: a616 loop15 asic startup diagnostic failure";
CM_ SG_ 2030 TRCM_a617_loop16AsicStartupDiagn "TRCM ECU: a617 loop16 asic startup diagnostic failure";
CM_ SG_ 2030 TRCM_a618_loop17AsicStartupDiagn "TRCM ECU: a618 loop17 asic startup diagnostic failure";
CM_ SG_ 2030 TRCM_a619_loop18AsicStartupDiagn "TRCM ECU: a619 loop18 asic startup diagnostic failure";
CM_ SG_ 2030 TRCM_a620_loop19AsicStartupDiagn "TRCM ECU: a620 loop19 asic startup diagnostic failure";
CM_ SG_ 2030 TRCM_a621_loop20AsicStartupDiagn "TRCM ECU: a621 loop20 asic startup diagnostic failure";
CM_ SG_ 2030 TRCM_a622_loop21AsicStartupDiagn "TRCM ECU: a622 loop21 asic startup diagnostic failure";
CM_ SG_ 2030 TRCM_a623_loop22AsicStartupDiagn "TRCM ECU: a623 loop22 asic startup diagnostic failure";
CM_ SG_ 2030 TRCM_a624_loop23AsicStartupDiagn "TRCM ECU: a624 loop23 asic startup diagnostic failure";
CM_ SG_ 2030 TRCM_a625_loop24AsicStartupDiagn "TRCM ECU: a625 loop24 asic startup diagnostic failure";
CM_ SG_ 2030 TRCM_a626_loop25AsicStartupDiagn "TRCM ECU: a626 loop25 asic startup diagnostic failure";
CM_ SG_ 2030 TRCM_a627_loop26AsicStartupDiagn "TRCM ECU: a627 loop26 asic startup diagnostic failure";
CM_ SG_ 2030 TRCM_a628_loop27AsicStartupDiagn "TRCM ECU: a628 loop27 asic startup diagnostic failure";
CM_ SG_ 2030 TRCM_a629_loop28AsicStartupDiagn "TRCM ECU: a629 loop28 asic startup diagnostic failure";
CM_ SG_ 2030 TRCM_a630_loop29AsicStartupDiagn "TRCM ECU: a630 loop29 asic startup diagnostic failure";
CM_ SG_ 2030 TRCM_a631_loop30AsicStartupDiagn "TRCM ECU: a631 loop30 asic startup diagnostic failure";
CM_ SG_ 2030 TRCM_a632_loop31AsicStartupDiagn "TRCM ECU: a632 loop31 asic startup diagnostic failure";
CM_ SG_ 2030 TRCM_a633_glacierInitialStatusFa "TRCM ECU: a633 glacier initial status failure";
CM_ SG_ 2030 TRCM_a634_glacierTraceabilityRea "TRCM ECU: a634 glacier traceability readout A0 A0 failure";
CM_ SG_ 2030 TRCM_a635_glacierTraceabilityRea "TRCM ECU: a635 glacier traceability readout B0 B0 failure";
CM_ SG_ 2030 TRCM_a636_glacierRegisterPattern "TRCM ECU: a636 glacier register pattern write failure";
CM_ SG_ 2030 TRCM_a637_glacierFixedPatternSel "TRCM ECU: a637 glacier fixed pattern self test failure";
CM_ SG_ 2030 TRCM_a638_glacierSelfTestEFailur "TRCM ECU: a638 glacier self test e failure";
CM_ SG_ 2030 TRCM_a639_glacierSelfTestFFailur "TRCM ECU: a639 glacier self test f failure";
CM_ SG_ 2030 TRCM_a640_glacierAnalogSelfTestF "TRCM ECU: a640 glacier analog self test failure";
CM_ SG_ 2030 TRCM_a641_glacierOscillatorVerif "TRCM ECU: a641 glacier oscillator verification failure";
CM_ SG_ 2030 TRCM_a642_glacierFinalStatusFail "TRCM ECU: a642 glacier final status failure";
CM_ SG_ 2030 TRCM_a643_glacierOffsetVerificat "TRCM ECU: a643 glacier offset verification failure";
CM_ SG_ 2030 TRCM_a644_glacierNormalOperation "TRCM ECU: a644 glacier normal operation failure";
CM_ SG_ 2030 TRCM_a645_glacierDeviceReset "TRCM ECU: a645 glacier device reset";
CM_ SG_ 2030 TRCM_a646_glacierDeviceFaulted "TRCM ECU: a646 glacier device faulted";
CM_ BO_ 2019 "TRCM ECU message: info";
CM_ SG_ 2019 TRCM_infoIndex "TRCM ECU: info index";
CM_ SG_ 2019 TRCM_infoBuildType "TRCM ECU: info build type";
CM_ SG_ 2019 TRCM_infoBuildConfigId "TRCM ECU: info build config id";
CM_ SG_ 2019 TRCM_infoHardwareId "TRCM ECU: info hardware id";
CM_ SG_ 2019 TRCM_infoComponentId "TRCM ECU: info component id";
CM_ SG_ 2019 TRCM_infoPcbaId "TRCM ECU: info pcba id";
CM_ SG_ 2019 TRCM_infoAssemblyId "TRCM ECU: info assembly id; raw 255 = signal not available (SNA)";
CM_ SG_ 2019 TRCM_infoUsageId "TRCM ECU: info usage id";
CM_ SG_ 2019 TRCM_infoSubUsageId "TRCM ECU: info sub usage id";
CM_ SG_ 2019 TRCM_infoAppCrc "TRCM ECU: info app crc";
CM_ SG_ 2019 TRCM_infoAppGitHash "TRCM ECU: info app git hash";
CM_ SG_ 2019 TRCM_infoBootGitHash "TRCM ECU: info boot git hash";
CM_ SG_ 2019 TRCM_infoBootUdsProtoVersion "TRCM ECU: info boot uds proto version";
CM_ SG_ 2019 TRCM_infoBootCrc "TRCM ECU: info boot crc";
CM_ BO_ 1641 "UDS ECU message: KOSTI asccm request";
CM_ SG_ 1641 UDS_KOSTIAsccmRequestData "UDS ECU: KOSTI asccm request data";
CM_ BO_ 1538 "UDS ECU message: bms request";
CM_ SG_ 1538 UDS_bmsRequestData "UDS ECU: bms request data";
CM_ BO_ 1579 "UDS ECU message: cc request";
CM_ SG_ 1579 UDS_ccRequestData "UDS ECU: cc request data";
CM_ BO_ 1539 "UDS ECU message: cmp request";
CM_ SG_ 1539 UDS_cmpRequestData "UDS ECU: cmp request data";
CM_ BO_ 1543 "UDS ECU message: cmpd request";
CM_ SG_ 1543 UDS_cmpdRequestData "UDS ECU: cmpd request data";
CM_ BO_ 1550 "UDS ECU message: cp request";
CM_ SG_ 1550 UDS_cpRequestData "UDS ECU: cp request data";
CM_ BO_ 1609 "UDS ECU message: das request";
CM_ SG_ 1609 UDS_dasRequestData "UDS ECU: das request data";
CM_ BO_ 1589 "UDS ECU message: di request";
CM_ SG_ 1589 UDS_diRequestData "UDS ECU: di request data";
CM_ BO_ 1541 "UDS ECU message: dif request";
CM_ SG_ 1541 UDS_difRequestData "UDS ECU: dif request data";
CM_ BO_ 1542 "UDS ECU message: dir request";
CM_ SG_ 1542 UDS_dirRequestData "UDS ECU: dir request data";
CM_ BO_ 1584 "UDS ECU message: epas3p request";
CM_ SG_ 1584 UDS_epas3pRequestData "UDS ECU: epas3p request data";
CM_ BO_ 1840 "UDS ECU message: epas3s request";
CM_ SG_ 1840 UDS_epas3sRequestData "UDS ECU: epas3s request data";
CM_ BO_ 1572 "UDS ECU message: epbl request";
CM_ SG_ 1572 UDS_epblRequestData_H "UDS ECU: epbl request data h";
CM_ SG_ 1572 UDS_epblRequestData_L "UDS ECU: epbl request data l";
CM_ BO_ 1574 "UDS ECU message: epbr request";
CM_ SG_ 1574 UDS_epbrRequestData_H "UDS ECU: epbr request data h";
CM_ SG_ 1574 UDS_epbrRequestData_L "UDS ECU: epbr request data l";
CM_ BO_ 1605 "UDS ECU message: esp request";
CM_ SG_ 1605 UDS_espRequestData "UDS ECU: esp request data";
CM_ BO_ 2015 "UDS ECU message: functional request";
CM_ SG_ 2015 UDS_functionalRequestData_0 "UDS ECU: functional request data 0";
CM_ SG_ 2015 UDS_functionalRequestData_1 "UDS ECU: functional request data 1";
CM_ SG_ 2015 UDS_functionalRequestData_2 "UDS ECU: functional request data 2";
CM_ SG_ 2015 UDS_functionalRequestData_3 "UDS ECU: functional request data 3";
CM_ SG_ 2015 UDS_functionalRequestData_4 "UDS ECU: functional request data 4";
CM_ SG_ 2015 UDS_functionalRequestData_5 "UDS ECU: functional request data 5";
CM_ SG_ 2015 UDS_functionalRequestData_6 "UDS ECU: functional request data 6";
CM_ SG_ 2015 UDS_functionalRequestData_7 "UDS ECU: functional request data 7";
CM_ BO_ 2014 "UDS ECU message: functional request CH";
CM_ SG_ 2014 UDS_functionalRequestDataCH "UDS ECU: functional request data CH";
CM_ BO_ 1552 "UDS ECU message: hvp request";
CM_ SG_ 1552 UDS_hvpRequestData "UDS ECU: hvp request data";
CM_ BO_ 1613 "UDS ECU message: ibst request";
CM_ SG_ 1613 UDS_ibstRequestData "UDS ECU: ibst request data";
CM_ BO_ 1560 "UDS ECU message: icr request";
CM_ SG_ 1560 UDS_icrRequestData "UDS ECU: icr request data";
CM_ BO_ 1603 "UDS ECU message: ocs1p request";
CM_ SG_ 1603 UDS_ocs1pRequestData "UDS ECU: ocs1p request data";
CM_ BO_ 1614 "UDS ECU message: park request";
CM_ SG_ 1614 UDS_parkRequestData "UDS ECU: park request data";
CM_ BO_ 1576 "UDS ECU message: pcs request";
CM_ SG_ 1576 UDS_pcsRequestData "UDS ECU: pcs request data";
CM_ BO_ 1634 "UDS ECU message: plg request";
CM_ SG_ 1634 UDS_plgRequestData "UDS ECU: plg request data";
CM_ BO_ 1568 "UDS ECU message: pm request";
CM_ SG_ 1568 UDS_pmRequestData "UDS ECU: pm request data";
CM_ BO_ 1604 "UDS ECU message: pmf request";
CM_ SG_ 1604 UDS_pmfRequestData "UDS ECU: pmf request data";
CM_ BO_ 1540 "UDS ECU message: pmr request";
CM_ SG_ 1540 UDS_pmrRequestData "UDS ECU: pmr request data";
CM_ BO_ 1734 "UDS ECU message: ptc request";
CM_ SG_ 1734 UDS_ptcRequestData "UDS ECU: ptc request data";
CM_ BO_ 1649 "UDS ECU message: radc request";
CM_ SG_ 1649 UDS_radcRequestData "UDS ECU: radc request data";
CM_ BO_ 1601 "UDS ECU message: rcm request";
CM_ SG_ 1601 UDS_rcmRequestData "UDS ECU: rcm request data";
CM_ BO_ 1664 "UDS ECU message: sccm request";
CM_ SG_ 1664 UDS_sccmRequestData "UDS ECU: sccm request data";
CM_ BO_ 1723 "UDS ECU message: sdcr request";
CM_ SG_ 1723 UDS_sdcrRequestData "UDS ECU: sdcr request data";
CM_ BO_ 1611 "UDS ECU message: tas request";
CM_ SG_ 1611 UDS_tasRequestData "UDS ECU: tas request data";
CM_ BO_ 1551 "UDS ECU message: thc request";
CM_ SG_ 1551 UDS_thcRequestData_H "UDS ECU: thc request data h";
CM_ SG_ 1551 UDS_thcRequestData_L "UDS ECU: thc request data l";
CM_ BO_ 1615 "UDS ECU message: tpms request";
CM_ SG_ 1615 UDS_tpmsRequestData "UDS ECU: tpms request data";
CM_ BO_ 1578 "UDS ECU message: vcbatt1 request";
CM_ SG_ 1578 UDS_vcbatt1RequestData "UDS ECU: vcbatt1 request data";
CM_ BO_ 1588 "UDS ECU message: vcbatt2 request";
CM_ SG_ 1588 UDS_vcbatt2RequestData "UDS ECU: vcbatt2 request data";
CM_ BO_ 1636 "UDS ECU message: vcbatt request";
CM_ SG_ 1636 UDS_vcbattRequestData "UDS ECU: vcbatt request data";
CM_ BO_ 1580 "UDS ECU message: vcfront1 request";
CM_ SG_ 1580 UDS_vcfront1RequestData "UDS ECU: vcfront1 request data";
CM_ BO_ 1582 "UDS ECU message: vcfront2 request";
CM_ SG_ 1582 UDS_vcfront2RequestData "UDS ECU: vcfront2 request data";
CM_ BO_ 1536 "UDS ECU message: vcfront request";
CM_ SG_ 1536 UDS_vcfrontRequestData "UDS ECU: vcfront request data";
CM_ BO_ 1570 "UDS ECU message: vcleft request";
CM_ SG_ 1570 UDS_vcleftRequestData_H "UDS ECU: vcleft request data h";
CM_ SG_ 1570 UDS_vcleftRequestData_L "UDS ECU: vcleft request data l";
CM_ BO_ 1544 "UDS ECU message: vcright request";
CM_ SG_ 1544 UDS_vcrightRequestData_H "UDS ECU: vcright request data h";
CM_ SG_ 1544 UDS_vcrightRequestData_L "UDS ECU: vcright request data l";
CM_ BO_ 1546 "UDS ECU message: vcsec request";
CM_ SG_ 1546 UDS_vcsecRequestData "UDS ECU: vcsec request data";
BA_DEF_ BO_ "GenMsgCycleTime" INT 0 3600000;
BA_DEF_ BO_ "GenMsgSendType" ENUM "Cyclic","NotUsed","NotUsed","NotUsed","NotUsed","NotUsed","NotUsed","IfActive","NoMsgSendType","NotUsed";
BA_DEF_ BO_ "VFrameFormat" ENUM "StandardCAN","ExtendedCAN","reserved","J1939PG","reserved","reserved","reserved","reserved","reserved","reserved","reserved","reserved","reserved","reserved","StandardCAN_FD","ExtendedCAN_FD";
BA_DEF_ BO_ "CANFD_BRS" ENUM "0","1";
BA_DEF_ SG_ "GenSigSNA" STRING;
BA_DEF_ SG_ "SystemSignalLongSymbol" STRING;
BA_DEF_ SG_ "Confidence" ENUM "validated","plausible","layout-only","contradicted";
BA_DEF_DEF_ "GenMsgCycleTime" 0;
BA_DEF_DEF_ "GenMsgSendType" "NoMsgSendType";
BA_DEF_DEF_ "VFrameFormat" "StandardCAN";
BA_DEF_DEF_ "CANFD_BRS" "1";
BA_DEF_DEF_ "GenSigSNA" "";
BA_DEF_DEF_ "SystemSignalLongSymbol" "";
BA_DEF_DEF_ "Confidence" "layout-only";
BA_ "GenMsgCycleTime" BO_ 2030 100;
BA_ "GenMsgSendType" BO_ 2030 0;
BA_ "GenMsgCycleTime" BO_ 2019 1000;
BA_ "GenMsgSendType" BO_ 2019 0;
BA_ "Confidence" SG_ 2030 TRCM_matrixIndex 1;
BA_ "SystemSignalLongSymbol" SG_ 2030 TRCM_a012_asm5TemperatureOutside "TRCM_a012_asm5TemperatureOutsideSignalRange";
BA_ "SystemSignalLongSymbol" SG_ 2030 TRCM_a014_asm3TemperatureOutside "TRCM_a014_asm3TemperatureOutsideSignalRange";
BA_ "SystemSignalLongSymbol" SG_ 2030 TRCM_a017_asm5TemperatureOutside "TRCM_a017_asm5TemperatureOutsideOperatingRange";
BA_ "SystemSignalLongSymbol" SG_ 2030 TRCM_a018_asm3TemperatureOutside "TRCM_a018_asm3TemperatureOutsideOperatingRange";
BA_ "SystemSignalLongSymbol" SG_ 2030 TRCM_a026_airbagAsicDiagnosticFa "TRCM_a026_airbagAsicDiagnosticFault";
BA_ "SystemSignalLongSymbol" SG_ 2030 TRCM_a027_airbagAsicDeploymentDi "TRCM_a027_airbagAsicDeploymentDiagnosticFault";
BA_ "SystemSignalLongSymbol" SG_ 2030 TRCM_a074_ais2120SelfTestXPositi "TRCM_a074_ais2120SelfTestXPositiveFailed";
BA_ "SystemSignalLongSymbol" SG_ 2030 TRCM_a075_ais2120SelfTestXNegati "TRCM_a075_ais2120SelfTestXNegativeFailed";
BA_ "SystemSignalLongSymbol" SG_ 2030 TRCM_a076_ais2120SelfTestYPositi "TRCM_a076_ais2120SelfTestYPositiveFailed";
BA_ "SystemSignalLongSymbol" SG_ 2030 TRCM_a077_ais2120SelfTestYNegati "TRCM_a077_ais2120SelfTestYNegativeFailed";
BA_ "SystemSignalLongSymbol" SG_ 2030 TRCM_a121_buckleStatusFrontLeftS "TRCM_a121_buckleStatusFrontLeftSignalNotOkay";
BA_ "SystemSignalLongSymbol" SG_ 2030 TRCM_a122_buckleStatusFrontRight "TRCM_a122_buckleStatusFrontRightSignalNotOkay";
BA_ "SystemSignalLongSymbol" SG_ 2030 TRCM_a123_buckleStatusRearLeftSi "TRCM_a123_buckleStatusRearLeftSignalNotOkay";
BA_ "SystemSignalLongSymbol" SG_ 2030 TRCM_a124_buckleStatusRearRightS "TRCM_a124_buckleStatusRearRightSignalNotOkay";
BA_ "SystemSignalLongSymbol" SG_ 2030 TRCM_a125_occupantClassification "TRCM_a125_occupantClassificationSignalNotOkay";
BA_ "SystemSignalLongSymbol" SG_ 2030 TRCM_a126_seatTrackPositionLeftS "TRCM_a126_seatTrackPositionLeftSignalNotOkay";
BA_ "SystemSignalLongSymbol" SG_ 2030 TRCM_a127_seatTrackPositionRight "TRCM_a127_seatTrackPositionRightSignalNotOkay";
BA_ "SystemSignalLongSymbol" SG_ 2030 TRCM_a137_ext1AsicSnoopTestFaile "TRCM_a137_ext1AsicSnoopTestFailed";
BA_ "SystemSignalLongSymbol" SG_ 2030 TRCM_a138_ext2AsicSnoopTestFaile "TRCM_a138_ext2AsicSnoopTestFailed";
BA_ "SystemSignalLongSymbol" SG_ 2030 TRCM_a145_frontCenterAccelReport "TRCM_a145_frontCenterAccelReportedError";
BA_ "SystemSignalLongSymbol" SG_ 2030 TRCM_a146_frontCenterAccelGenera "TRCM_a146_frontCenterAccelGeneralIssue";
BA_ "SystemSignalLongSymbol" SG_ 2030 TRCM_a147_frontCenterAccelElectr "TRCM_a147_frontCenterAccelElectricalIssue";
BA_ "SystemSignalLongSymbol" SG_ 2030 TRCM_a148_frontCenterAccelConfig "TRCM_a148_frontCenterAccelConfigError";
BA_ "SystemSignalLongSymbol" SG_ 2030 TRCM_a149_frontCenterAccelSignal "TRCM_a149_frontCenterAccelSignalMonitor";
BA_ "SystemSignalLongSymbol" SG_ 2030 TRCM_a150_frontLeftAccelReported "TRCM_a150_frontLeftAccelReportedError";
BA_ "SystemSignalLongSymbol" SG_ 2030 TRCM_a151_frontLeftAccelGeneralI "TRCM_a151_frontLeftAccelGeneralIssue";
BA_ "SystemSignalLongSymbol" SG_ 2030 TRCM_a152_frontLeftAccelElectric "TRCM_a152_frontLeftAccelElectricalIssue";
BA_ "SystemSignalLongSymbol" SG_ 2030 TRCM_a153_frontLeftAccelConfigEr "TRCM_a153_frontLeftAccelConfigError";
BA_ "SystemSignalLongSymbol" SG_ 2030 TRCM_a154_frontLeftAccelSignalMo "TRCM_a154_frontLeftAccelSignalMonitor";
BA_ "SystemSignalLongSymbol" SG_ 2030 TRCM_a155_frontLeftDoorPressureR "TRCM_a155_frontLeftDoorPressureReportedError";
BA_ "SystemSignalLongSymbol" SG_ 2030 TRCM_a156_frontLeftDoorPressureG "TRCM_a156_frontLeftDoorPressureGeneralIssue";
BA_ "SystemSignalLongSymbol" SG_ 2030 TRCM_a157_frontLeftDoorPressureE "TRCM_a157_frontLeftDoorPressureElectricalIssue";
BA_ "SystemSignalLongSymbol" SG_ 2030 TRCM_a158_frontLeftDoorPressureC "TRCM_a158_frontLeftDoorPressureConfigError";
BA_ "SystemSignalLongSymbol" SG_ 2030 TRCM_a159_frontLeftDoorPressureS "TRCM_a159_frontLeftDoorPressureSignalMonitor";
BA_ "SystemSignalLongSymbol" SG_ 2030 TRCM_a160_frontRightAccelReporte "TRCM_a160_frontRightAccelReportedError";
BA_ "SystemSignalLongSymbol" SG_ 2030 TRCM_a161_frontRightAccelGeneral "TRCM_a161_frontRightAccelGeneralIssue";
BA_ "SystemSignalLongSymbol" SG_ 2030 TRCM_a162_frontRightAccelElectri "TRCM_a162_frontRightAccelElectricalIssue";
BA_ "SystemSignalLongSymbol" SG_ 2030 TRCM_a163_frontRightAccelConfigE "TRCM_a163_frontRightAccelConfigError";
BA_ "SystemSignalLongSymbol" SG_ 2030 TRCM_a164_frontRightAccelSignalM "TRCM_a164_frontRightAccelSignalMonitor";
BA_ "SystemSignalLongSymbol" SG_ 2030 TRCM_a165_frontRightDoorPressure "TRCM_a165_frontRightDoorPressureReportedError";
BA_ "SystemSignalLongSymbol" SG_ 2030 TRCM_a166_frontRightDoorPressure "TRCM_a166_frontRightDoorPressureGeneralIssue";
BA_ "SystemSignalLongSymbol" SG_ 2030 TRCM_a167_frontRightDoorPressure "TRCM_a167_frontRightDoorPressureElectricalIssue";
BA_ "SystemSignalLongSymbol" SG_ 2030 TRCM_a168_frontRightDoorPressure "TRCM_a168_frontRightDoorPressureConfigError";
BA_ "SystemSignalLongSymbol" SG_ 2030 TRCM_a169_frontRightDoorPressure "TRCM_a169_frontRightDoorPressureSignalMonitor";
BA_ "SystemSignalLongSymbol" SG_ 2030 TRCM_a170_leftBPillarAccelReport "TRCM_a170_leftBPillarAccelReportedError";
BA_ "SystemSignalLongSymbol" SG_ 2030 TRCM_a171_leftBPillarAccelGenera "TRCM_a171_leftBPillarAccelGeneralIssue";
BA_ "SystemSignalLongSymbol" SG_ 2030 TRCM_a172_leftBPillarAccelElectr "TRCM_a172_leftBPillarAccelElectricalIssue";
BA_ "SystemSignalLongSymbol" SG_ 2030 TRCM_a173_leftBPillarAccelConfig "TRCM_a173_leftBPillarAccelConfigError";
BA_ "SystemSignalLongSymbol" SG_ 2030 TRCM_a174_leftBPillarAccelSignal "TRCM_a174_leftBPillarAccelSignalMonitor";
BA_ "SystemSignalLongSymbol" SG_ 2030 TRCM_a175_leftCPillarAccelReport "TRCM_a175_leftCPillarAccelReportedError";
BA_ "SystemSignalLongSymbol" SG_ 2030 TRCM_a176_leftCPillarAccelGenera "TRCM_a176_leftCPillarAccelGeneralIssue";
BA_ "SystemSignalLongSymbol" SG_ 2030 TRCM_a177_leftCPillarAccelElectr "TRCM_a177_leftCPillarAccelElectricalIssue";
BA_ "SystemSignalLongSymbol" SG_ 2030 TRCM_a178_leftCPillarAccelConfig "TRCM_a178_leftCPillarAccelConfigError";
BA_ "SystemSignalLongSymbol" SG_ 2030 TRCM_a179_leftCPillarAccelSignal "TRCM_a179_leftCPillarAccelSignalMonitor";
BA_ "SystemSignalLongSymbol" SG_ 2030 TRCM_a190_rearLeftDoorPressureRe "TRCM_a190_rearLeftDoorPressureReportedError";
BA_ "SystemSignalLongSymbol" SG_ 2030 TRCM_a191_rearLeftDoorPressureGe "TRCM_a191_rearLeftDoorPressureGeneralIssue";
BA_ "SystemSignalLongSymbol" SG_ 2030 TRCM_a192_rearLeftDoorPressureEl "TRCM_a192_rearLeftDoorPressureElectricalIssue";
BA_ "SystemSignalLongSymbol" SG_ 2030 TRCM_a193_rearLeftDoorPressureCo "TRCM_a193_rearLeftDoorPressureConfigError";
BA_ "SystemSignalLongSymbol" SG_ 2030 TRCM_a194_rearLeftDoorPressureSi "TRCM_a194_rearLeftDoorPressureSignalMonitor";
BA_ "SystemSignalLongSymbol" SG_ 2030 TRCM_a195_rearRightDoorPressureR "TRCM_a195_rearRightDoorPressureReportedError";
BA_ "SystemSignalLongSymbol" SG_ 2030 TRCM_a196_rearRightDoorPressureG "TRCM_a196_rearRightDoorPressureGeneralIssue";
BA_ "SystemSignalLongSymbol" SG_ 2030 TRCM_a197_rearRightDoorPressureE "TRCM_a197_rearRightDoorPressureElectricalIssue";
BA_ "SystemSignalLongSymbol" SG_ 2030 TRCM_a198_rearRightDoorPressureC "TRCM_a198_rearRightDoorPressureConfigError";
BA_ "SystemSignalLongSymbol" SG_ 2030 TRCM_a199_rearRightDoorPressureS "TRCM_a199_rearRightDoorPressureSignalMonitor";
BA_ "SystemSignalLongSymbol" SG_ 2030 TRCM_a200_rightBPillarAccelRepor "TRCM_a200_rightBPillarAccelReportedError";
BA_ "SystemSignalLongSymbol" SG_ 2030 TRCM_a201_rightBPillarAccelGener "TRCM_a201_rightBPillarAccelGeneralIssue";
BA_ "SystemSignalLongSymbol" SG_ 2030 TRCM_a202_rightBPillarAccelElect "TRCM_a202_rightBPillarAccelElectricalIssue";
BA_ "SystemSignalLongSymbol" SG_ 2030 TRCM_a203_rightBPillarAccelConfi "TRCM_a203_rightBPillarAccelConfigError";
BA_ "SystemSignalLongSymbol" SG_ 2030 TRCM_a204_rightBPillarAccelSigna "TRCM_a204_rightBPillarAccelSignalMonitor";
BA_ "SystemSignalLongSymbol" SG_ 2030 TRCM_a205_rightCPillarAccelRepor "TRCM_a205_rightCPillarAccelReportedError";
BA_ "SystemSignalLongSymbol" SG_ 2030 TRCM_a206_rightCPillarAccelGener "TRCM_a206_rightCPillarAccelGeneralIssue";
BA_ "SystemSignalLongSymbol" SG_ 2030 TRCM_a207_rightCPillarAccelElect "TRCM_a207_rightCPillarAccelElectricalIssue";
BA_ "SystemSignalLongSymbol" SG_ 2030 TRCM_a208_rightCPillarAccelConfi "TRCM_a208_rightCPillarAccelConfigError";
BA_ "SystemSignalLongSymbol" SG_ 2030 TRCM_a209_rightCPillarAccelSigna "TRCM_a209_rightCPillarAccelSignalMonitor";
BA_ "SystemSignalLongSymbol" SG_ 2030 TRCM_a300_driverAirbagStage1Supp "TRCM_a300_driverAirbagStage1Suppressed";
BA_ "SystemSignalLongSymbol" SG_ 2030 TRCM_a301_passengerAirbagStage1S "TRCM_a301_passengerAirbagStage1Suppressed";
BA_ "SystemSignalLongSymbol" SG_ 2030 TRCM_a302_driverAirbagStage2Supp "TRCM_a302_driverAirbagStage2Suppressed";
BA_ "SystemSignalLongSymbol" SG_ 2030 TRCM_a303_driverAirbagActiveVent "TRCM_a303_driverAirbagActiveVentSuppressed";
BA_ "SystemSignalLongSymbol" SG_ 2030 TRCM_a304_passengerAirbagStage2S "TRCM_a304_passengerAirbagStage2Suppressed";
BA_ "SystemSignalLongSymbol" SG_ 2030 TRCM_a305_passengerAirbagActiveV "TRCM_a305_passengerAirbagActiveVentSuppressed";
BA_ "SystemSignalLongSymbol" SG_ 2030 TRCM_a306_inboardSeatAirbagSuppr "TRCM_a306_inboardSeatAirbagSuppressed";
BA_ "SystemSignalLongSymbol" SG_ 2030 TRCM_a308_kneeAirbagLeftSuppress "TRCM_a308_kneeAirbagLeftSuppressed";
BA_ "SystemSignalLongSymbol" SG_ 2030 TRCM_a309_kneeAirbagRightSuppres "TRCM_a309_kneeAirbagRightSuppressed";
BA_ "SystemSignalLongSymbol" SG_ 2030 TRCM_a310_curtainAirbagLeftSuppr "TRCM_a310_curtainAirbagLeftSuppressed";
BA_ "SystemSignalLongSymbol" SG_ 2030 TRCM_a311_curtainAirbagRightSupp "TRCM_a311_curtainAirbagRightSuppressed";
BA_ "SystemSignalLongSymbol" SG_ 2030 TRCM_a312_seatbeltLoadLimiterFro "TRCM_a312_seatbeltLoadLimiterFrontLeftSuppressed";
BA_ "SystemSignalLongSymbol" SG_ 2030 TRCM_a313_seatbeltLoadLimiterFro "TRCM_a313_seatbeltLoadLimiterFrontRightSuppressed";
BA_ "SystemSignalLongSymbol" SG_ 2030 TRCM_a314_seatbeltShoulderPreten "TRCM_a314_seatbeltShoulderPretensionerFrontLeftSuppressed";
BA_ "SystemSignalLongSymbol" SG_ 2030 TRCM_a315_seatbeltShoulderPreten "TRCM_a315_seatbeltShoulderPretensionerFrontRightSuppressed";
BA_ "SystemSignalLongSymbol" SG_ 2030 TRCM_a316_seatbeltLapPretensione "TRCM_a316_seatbeltLapPretensionerFrontLeftSuppressed";
BA_ "SystemSignalLongSymbol" SG_ 2030 TRCM_a317_seatbeltLapPretensione "TRCM_a317_seatbeltLapPretensionerFrontRightSuppressed";
BA_ "SystemSignalLongSymbol" SG_ 2030 TRCM_a318_outboardSeatAirbagLeft "TRCM_a318_outboardSeatAirbagLeftSuppressed";
BA_ "SystemSignalLongSymbol" SG_ 2030 TRCM_a319_outboardSeatAirbagRigh "TRCM_a319_outboardSeatAirbagRightSuppressed";
BA_ "SystemSignalLongSymbol" SG_ 2030 TRCM_a320_hoodLifterLeftSuppress "TRCM_a320_hoodLifterLeftSuppressed";
BA_ "SystemSignalLongSymbol" SG_ 2030 TRCM_a321_hoodLifterRightSuppres "TRCM_a321_hoodLifterRightSuppressed";
BA_ "SystemSignalLongSymbol" SG_ 2030 TRCM_a322_seatbeltShoulderPreten "TRCM_a322_seatbeltShoulderPretensionerRearLeftSuppressed";
BA_ "SystemSignalLongSymbol" SG_ 2030 TRCM_a323_seatbeltShoulderPreten "TRCM_a323_seatbeltShoulderPretensionerRearRightSuppressed";
BA_ "SystemSignalLongSymbol" SG_ 2030 TRCM_a332_driverAirbagStage1Depl "TRCM_a332_driverAirbagStage1Deployed";
BA_ "SystemSignalLongSymbol" SG_ 2030 TRCM_a333_passengerAirbagStage1D "TRCM_a333_passengerAirbagStage1Deployed";
BA_ "SystemSignalLongSymbol" SG_ 2030 TRCM_a334_driverAirbagStage2Depl "TRCM_a334_driverAirbagStage2Deployed";
BA_ "SystemSignalLongSymbol" SG_ 2030 TRCM_a335_driverAirbagActiveVent "TRCM_a335_driverAirbagActiveVentDeployed";
BA_ "SystemSignalLongSymbol" SG_ 2030 TRCM_a336_passengerAirbagStage2D "TRCM_a336_passengerAirbagStage2Deployed";
BA_ "SystemSignalLongSymbol" SG_ 2030 TRCM_a337_passengerAirbagActiveV "TRCM_a337_passengerAirbagActiveVentDeployed";
BA_ "SystemSignalLongSymbol" SG_ 2030 TRCM_a338_inboardSeatAirbagDeplo "TRCM_a338_inboardSeatAirbagDeployed";
BA_ "SystemSignalLongSymbol" SG_ 2030 TRCM_a341_kneeAirbagRightDeploye "TRCM_a341_kneeAirbagRightDeployed";
BA_ "SystemSignalLongSymbol" SG_ 2030 TRCM_a342_curtainAirbagLeftDeplo "TRCM_a342_curtainAirbagLeftDeployed";
BA_ "SystemSignalLongSymbol" SG_ 2030 TRCM_a343_curtainAirbagRightDepl "TRCM_a343_curtainAirbagRightDeployed";
BA_ "SystemSignalLongSymbol" SG_ 2030 TRCM_a344_seatbeltLoadLimiterFro "TRCM_a344_seatbeltLoadLimiterFrontLeftDeployed";
BA_ "SystemSignalLongSymbol" SG_ 2030 TRCM_a345_seatbeltLoadLimiterFro "TRCM_a345_seatbeltLoadLimiterFrontRightDeployed";
BA_ "SystemSignalLongSymbol" SG_ 2030 TRCM_a346_seatbeltShoulderPreten "TRCM_a346_seatbeltShoulderPretensionerFrontLeftDeployed";
BA_ "SystemSignalLongSymbol" SG_ 2030 TRCM_a347_seatbeltShoulderPreten "TRCM_a347_seatbeltShoulderPretensionerFrontRightDeployed";
BA_ "SystemSignalLongSymbol" SG_ 2030 TRCM_a348_seatbeltLapPretensione "TRCM_a348_seatbeltLapPretensionerFrontLeftDeployed";
BA_ "SystemSignalLongSymbol" SG_ 2030 TRCM_a349_seatbeltLapPretensione "TRCM_a349_seatbeltLapPretensionerFrontRightDeployed";
BA_ "SystemSignalLongSymbol" SG_ 2030 TRCM_a350_outboardSeatAirbagLeft "TRCM_a350_outboardSeatAirbagLeftDeployed";
BA_ "SystemSignalLongSymbol" SG_ 2030 TRCM_a351_outboardSeatAirbagRigh "TRCM_a351_outboardSeatAirbagRightDeployed";
BA_ "SystemSignalLongSymbol" SG_ 2030 TRCM_a353_hoodLifterRightDeploye "TRCM_a353_hoodLifterRightDeployed";
BA_ "SystemSignalLongSymbol" SG_ 2030 TRCM_a354_seatbeltShoulderPreten "TRCM_a354_seatbeltShoulderPretensionerRearLeftDeployed";
BA_ "SystemSignalLongSymbol" SG_ 2030 TRCM_a355_seatbeltShoulderPreten "TRCM_a355_seatbeltShoulderPretensionerRearRightDeployed";
BA_ "SystemSignalLongSymbol" SG_ 2030 TRCM_a364_safingEngine0NoValidDa "TRCM_a364_safingEngine0NoValidData";
BA_ "SystemSignalLongSymbol" SG_ 2030 TRCM_a365_safingEngine1NoValidDa "TRCM_a365_safingEngine1NoValidData";
BA_ "SystemSignalLongSymbol" SG_ 2030 TRCM_a366_safingEngine2NoValidDa "TRCM_a366_safingEngine2NoValidData";
BA_ "SystemSignalLongSymbol" SG_ 2030 TRCM_a367_safingEngine3NoValidDa "TRCM_a367_safingEngine3NoValidData";
BA_ "SystemSignalLongSymbol" SG_ 2030 TRCM_a368_safingEngine4NoValidDa "TRCM_a368_safingEngine4NoValidData";
BA_ "SystemSignalLongSymbol" SG_ 2030 TRCM_a369_safingEngine5NoValidDa "TRCM_a369_safingEngine5NoValidData";
BA_ "SystemSignalLongSymbol" SG_ 2030 TRCM_a370_safingEngine6NoValidDa "TRCM_a370_safingEngine6NoValidData";
BA_ "SystemSignalLongSymbol" SG_ 2030 TRCM_a371_safingEngine7NoValidDa "TRCM_a371_safingEngine7NoValidData";
BA_ "SystemSignalLongSymbol" SG_ 2030 TRCM_a372_safingEngine8NoValidDa "TRCM_a372_safingEngine8NoValidData";
BA_ "SystemSignalLongSymbol" SG_ 2030 TRCM_a373_safingEngine9NoValidDa "TRCM_a373_safingEngine9NoValidData";
BA_ "SystemSignalLongSymbol" SG_ 2030 TRCM_a374_safingEngine10NoValidD "TRCM_a374_safingEngine10NoValidData";
BA_ "SystemSignalLongSymbol" SG_ 2030 TRCM_a375_safingEngine11NoValidD "TRCM_a375_safingEngine11NoValidData";
BA_ "SystemSignalLongSymbol" SG_ 2030 TRCM_a376_safingEngine12NoValidD "TRCM_a376_safingEngine12NoValidData";
BA_ "SystemSignalLongSymbol" SG_ 2030 TRCM_a377_safingEngine13NoValidD "TRCM_a377_safingEngine13NoValidData";
BA_ "SystemSignalLongSymbol" SG_ 2030 TRCM_a378_safingEngine14NoValidD "TRCM_a378_safingEngine14NoValidData";
BA_ "SystemSignalLongSymbol" SG_ 2030 TRCM_a379_safingEngine15NoValidD "TRCM_a379_safingEngine15NoValidData";
BA_ "SystemSignalLongSymbol" SG_ 2030 TRCM_a380_safingEngine16NoValidD "TRCM_a380_safingEngine16NoValidData";
BA_ "SystemSignalLongSymbol" SG_ 2030 TRCM_a381_safingEngine17NoValidD "TRCM_a381_safingEngine17NoValidData";
BA_ "SystemSignalLongSymbol" SG_ 2030 TRCM_a382_safingEngine18NoValidD "TRCM_a382_safingEngine18NoValidData";
BA_ "SystemSignalLongSymbol" SG_ 2030 TRCM_a383_safingEngine19NoValidD "TRCM_a383_safingEngine19NoValidData";
BA_ "SystemSignalLongSymbol" SG_ 2030 TRCM_a384_safingEngine20NoValidD "TRCM_a384_safingEngine20NoValidData";
BA_ "SystemSignalLongSymbol" SG_ 2030 TRCM_a385_safingEngine21NoValidD "TRCM_a385_safingEngine21NoValidData";
BA_ "SystemSignalLongSymbol" SG_ 2030 TRCM_a390_systemAsicClockOrOpera "TRCM_a390_systemAsicClockOrOperatingStateError";
BA_ "SystemSignalLongSymbol" SG_ 2030 TRCM_a391_extAsic1ClockOrOperati "TRCM_a391_extAsic1ClockOrOperatingStateError";
BA_ "SystemSignalLongSymbol" SG_ 2030 TRCM_a392_extAsic2ClockOrOperati "TRCM_a392_extAsic2ClockOrOperatingStateError";
BA_ "SystemSignalLongSymbol" SG_ 2030 TRCM_a393_depAdcConvertRatioErro "TRCM_a393_depAdcConvertRatioError";
BA_ "SystemSignalLongSymbol" SG_ 2030 TRCM_a394_gspiGlobalStatusWordEr "TRCM_a394_gspiGlobalStatusWordError";
BA_ "SystemSignalLongSymbol" SG_ 2030 TRCM_a396_spiCommunicationProgra "TRCM_a396_spiCommunicationProgramError";
BA_ "SystemSignalLongSymbol" SG_ 2030 TRCM_a400_driverAirbagStage1Issu "TRCM_a400_driverAirbagStage1Issue";
BA_ "SystemSignalLongSymbol" SG_ 2030 TRCM_a401_passengerAirbagStage1I "TRCM_a401_passengerAirbagStage1Issue";
BA_ "SystemSignalLongSymbol" SG_ 2030 TRCM_a402_driverAirbagStage2Issu "TRCM_a402_driverAirbagStage2Issue";
BA_ "SystemSignalLongSymbol" SG_ 2030 TRCM_a403_driverAirbagActiveVent "TRCM_a403_driverAirbagActiveVentIssue";
BA_ "SystemSignalLongSymbol" SG_ 2030 TRCM_a404_passengerAirbagStage2I "TRCM_a404_passengerAirbagStage2Issue";
BA_ "SystemSignalLongSymbol" SG_ 2030 TRCM_a405_passengerAirbagActiveV "TRCM_a405_passengerAirbagActiveVentIssue";
BA_ "SystemSignalLongSymbol" SG_ 2030 TRCM_a411_curtainAirbagRightIssu "TRCM_a411_curtainAirbagRightIssue";
BA_ "SystemSignalLongSymbol" SG_ 2030 TRCM_a412_seatbeltLoadLimiterFro "TRCM_a412_seatbeltLoadLimiterFrontLeftIssue";
BA_ "SystemSignalLongSymbol" SG_ 2030 TRCM_a413_seatbeltLoadLimiterFro "TRCM_a413_seatbeltLoadLimiterFrontRightIssue";
BA_ "SystemSignalLongSymbol" SG_ 2030 TRCM_a414_seatbeltShoulderPreten "TRCM_a414_seatbeltShoulderPretensionerFrontLeftIssue";
BA_ "SystemSignalLongSymbol" SG_ 2030 TRCM_a415_seatbeltShoulderPreten "TRCM_a415_seatbeltShoulderPretensionerFrontRightIssue";
BA_ "SystemSignalLongSymbol" SG_ 2030 TRCM_a416_seatbeltLapPretensione "TRCM_a416_seatbeltLapPretensionerFrontLeftIssue";
BA_ "SystemSignalLongSymbol" SG_ 2030 TRCM_a417_seatbeltLapPretensione "TRCM_a417_seatbeltLapPretensionerFrontRightIssue";
BA_ "SystemSignalLongSymbol" SG_ 2030 TRCM_a418_outboardSeatAirbagLeft "TRCM_a418_outboardSeatAirbagLeftIssue";
BA_ "SystemSignalLongSymbol" SG_ 2030 TRCM_a419_outboardSeatAirbagRigh "TRCM_a419_outboardSeatAirbagRightIssue";
BA_ "SystemSignalLongSymbol" SG_ 2030 TRCM_a422_seatbeltShoulderPreten "TRCM_a422_seatbeltShoulderPretensionerRearLeftIssue";
BA_ "SystemSignalLongSymbol" SG_ 2030 TRCM_a423_seatbeltShoulderPreten "TRCM_a423_seatbeltShoulderPretensionerRearRightIssue";
BA_ "SystemSignalLongSymbol" SG_ 2030 TRCM_a432_driverAirbagStage1Conf "TRCM_a432_driverAirbagStage1ConfigError";
BA_ "SystemSignalLongSymbol" SG_ 2030 TRCM_a433_passengerAirbagStage1C "TRCM_a433_passengerAirbagStage1ConfigError";
BA_ "SystemSignalLongSymbol" SG_ 2030 TRCM_a434_driverAirbagStage2Conf "TRCM_a434_driverAirbagStage2ConfigError";
BA_ "SystemSignalLongSymbol" SG_ 2030 TRCM_a435_driverAirbagActiveVent "TRCM_a435_driverAirbagActiveVentConfigError";
BA_ "SystemSignalLongSymbol" SG_ 2030 TRCM_a436_passengerAirbagStage2C "TRCM_a436_passengerAirbagStage2ConfigError";
BA_ "SystemSignalLongSymbol" SG_ 2030 TRCM_a437_passengerAirbagActiveV "TRCM_a437_passengerAirbagActiveVentConfigError";
BA_ "SystemSignalLongSymbol" SG_ 2030 TRCM_a438_inboardSeatAirbagConfi "TRCM_a438_inboardSeatAirbagConfigError";
BA_ "SystemSignalLongSymbol" SG_ 2030 TRCM_a440_kneeAirbagLeftConfigEr "TRCM_a440_kneeAirbagLeftConfigError";
BA_ "SystemSignalLongSymbol" SG_ 2030 TRCM_a441_kneeAirbagRightConfigE "TRCM_a441_kneeAirbagRightConfigError";
BA_ "SystemSignalLongSymbol" SG_ 2030 TRCM_a442_curtainAirbagLeftConfi "TRCM_a442_curtainAirbagLeftConfigError";
BA_ "SystemSignalLongSymbol" SG_ 2030 TRCM_a443_curtainAirbagRightConf "TRCM_a443_curtainAirbagRightConfigError";
BA_ "SystemSignalLongSymbol" SG_ 2030 TRCM_a444_seatbeltLoadLimiterFro "TRCM_a444_seatbeltLoadLimiterFrontLeftConfigError";
BA_ "SystemSignalLongSymbol" SG_ 2030 TRCM_a445_seatbeltLoadLimiterFro "TRCM_a445_seatbeltLoadLimiterFrontRightConfigError";
BA_ "SystemSignalLongSymbol" SG_ 2030 TRCM_a446_seatbeltShoulderPreten "TRCM_a446_seatbeltShoulderPretensionerFrontLeftConfigError";
BA_ "SystemSignalLongSymbol" SG_ 2030 TRCM_a447_seatbeltShoulderPreten "TRCM_a447_seatbeltShoulderPretensionerFrontRightConfigError";
BA_ "SystemSignalLongSymbol" SG_ 2030 TRCM_a448_seatbeltLapPretensione "TRCM_a448_seatbeltLapPretensionerFrontLeftConfigError";
BA_ "SystemSignalLongSymbol" SG_ 2030 TRCM_a449_seatbeltLapPretensione "TRCM_a449_seatbeltLapPretensionerFrontRightConfigError";
BA_ "SystemSignalLongSymbol" SG_ 2030 TRCM_a450_outboardSeatAirbagLeft "TRCM_a450_outboardSeatAirbagLeftConfigError";
BA_ "SystemSignalLongSymbol" SG_ 2030 TRCM_a451_outboardSeatAirbagRigh "TRCM_a451_outboardSeatAirbagRightConfigError";
BA_ "SystemSignalLongSymbol" SG_ 2030 TRCM_a452_hoodLifterLeftConfigEr "TRCM_a452_hoodLifterLeftConfigError";
BA_ "SystemSignalLongSymbol" SG_ 2030 TRCM_a453_hoodLifterRightConfigE "TRCM_a453_hoodLifterRightConfigError";
BA_ "SystemSignalLongSymbol" SG_ 2030 TRCM_a454_seatbeltShoulderPreten "TRCM_a454_seatbeltShoulderPretensionerRearLeftConfigError";
BA_ "SystemSignalLongSymbol" SG_ 2030 TRCM_a455_seatbeltShoulderPreten "TRCM_a455_seatbeltShoulderPretensionerRearRightConfigError";
BA_ "SystemSignalLongSymbol" SG_ 2030 TRCM_a545_erCapBelowAutarkyThres "TRCM_a545_erCapBelowAutarkyThreshold";
BA_ "SystemSignalLongSymbol" SG_ 2030 TRCM_a546_sensorValuesFaultedByS "TRCM_a546_sensorValuesFaultedBySmart";
BA_ "SystemSignalLongSymbol" SG_ 2030 TRCM_a550_AlgoWake_RCM_WAKE_FRON "TRCM_a550_AlgoWake_RCM_WAKE_FRONT";
BA_ "SystemSignalLongSymbol" SG_ 2030 TRCM_a553_AlgoWake_RCM_WAKE_RIGH "TRCM_a553_AlgoWake_RCM_WAKE_RIGHT";
BA_ "SystemSignalLongSymbol" SG_ 2030 TRCM_a554_AlgoWake_PAS_LH_PLAUSI "TRCM_a554_AlgoWake_PAS_LH_PLAUSI_FRONT";
BA_ "SystemSignalLongSymbol" SG_ 2030 TRCM_a555_AlgoWake_PAS_LH_PLAUSI "TRCM_a555_AlgoWake_PAS_LH_PLAUSI_REAR";
BA_ "SystemSignalLongSymbol" SG_ 2030 TRCM_a557_AlgoWake_PAS_RH_PLAUSI "TRCM_a557_AlgoWake_PAS_RH_PLAUSI_FRONT";
BA_ "SystemSignalLongSymbol" SG_ 2030 TRCM_a558_AlgoWake_PAS_RH_PLAUSI "TRCM_a558_AlgoWake_PAS_RH_PLAUSI_REAR";
BA_ "SystemSignalLongSymbol" SG_ 2030 TRCM_a560_AlgoWake_RCM_WAKE_ROLL "TRCM_a560_AlgoWake_RCM_WAKE_ROLL_LEFT";
BA_ "SystemSignalLongSymbol" SG_ 2030 TRCM_a561_AlgoWake_RCM_WAKE_ROLL "TRCM_a561_AlgoWake_RCM_WAKE_ROLL_RIGHT";
BA_ "SystemSignalLongSymbol" SG_ 2030 TRCM_a562_AlgoWake_RCM_AWAKE_FRO "TRCM_a562_AlgoWake_RCM_AWAKE_FRONT";
BA_ "SystemSignalLongSymbol" SG_ 2030 TRCM_a563_AlgoWake_RCM_AWAKE_REA "TRCM_a563_AlgoWake_RCM_AWAKE_REAR";
BA_ "SystemSignalLongSymbol" SG_ 2030 TRCM_a564_AlgoWake_RCM_AWAKE_LEF "TRCM_a564_AlgoWake_RCM_AWAKE_LEFT";
BA_ "SystemSignalLongSymbol" SG_ 2030 TRCM_a565_AlgoWake_RCM_AWAKE_RIG "TRCM_a565_AlgoWake_RCM_AWAKE_RIGHT";
BA_ "SystemSignalLongSymbol" SG_ 2030 TRCM_a566_AlgoWake_RCM_AWAKE_ROL "TRCM_a566_AlgoWake_RCM_AWAKE_ROLL";
BA_ "SystemSignalLongSymbol" SG_ 2030 TRCM_a570_AlgoWake_PAS_WAKE_RIGH "TRCM_a570_AlgoWake_PAS_WAKE_RIGHT";
BA_ "SystemSignalLongSymbol" SG_ 2030 TRCM_a576_AlgoWake_IMPACT_FINISH "TRCM_a576_AlgoWake_IMPACT_FINISH_X";
BA_ "SystemSignalLongSymbol" SG_ 2030 TRCM_a577_AlgoWake_IMPACT_FINISH "TRCM_a577_AlgoWake_IMPACT_FINISH_Y";
BA_ "SystemSignalLongSymbol" SG_ 2030 TRCM_a578_AlgoWake_IMPACT_FINISH "TRCM_a578_AlgoWake_IMPACT_FINISH_ROLL";
BA_ "SystemSignalLongSymbol" SG_ 2030 TRCM_a581_AlgoWake_RCM_ENABLED_R "TRCM_a581_AlgoWake_RCM_ENABLED_ROLL";
BA_ "SystemSignalLongSymbol" SG_ 2030 TRCM_a590_pitchRateOffsetPosLimi "TRCM_a590_pitchRateOffsetPosLimit";
BA_ "SystemSignalLongSymbol" SG_ 2030 TRCM_a591_pitchRateOffsetNegLimi "TRCM_a591_pitchRateOffsetNegLimit";
BA_ "SystemSignalLongSymbol" SG_ 2030 TRCM_a594_longitudinalAccelOffse "TRCM_a594_longitudinalAccelOffsetPosLimit";
BA_ "SystemSignalLongSymbol" SG_ 2030 TRCM_a595_longitudinalAccelOffse "TRCM_a595_longitudinalAccelOffsetNegLimit";
BA_ "SystemSignalLongSymbol" SG_ 2030 TRCM_a596_lateralAccelOffsetPosL "TRCM_a596_lateralAccelOffsetPosLimit";
BA_ "SystemSignalLongSymbol" SG_ 2030 TRCM_a597_lateralAccelOffsetNegL "TRCM_a597_lateralAccelOffsetNegLimit";
BA_ "SystemSignalLongSymbol" SG_ 2030 TRCM_a598_verticalAccelOffsetPos "TRCM_a598_verticalAccelOffsetPosLimit";
BA_ "SystemSignalLongSymbol" SG_ 2030 TRCM_a599_verticalAccelOffsetNeg "TRCM_a599_verticalAccelOffsetNegLimit";
BA_ "SystemSignalLongSymbol" SG_ 2030 TRCM_a600_airbagAsicStartupFailu "TRCM_a600_airbagAsicStartupFailure";
BA_ "SystemSignalLongSymbol" SG_ 2030 TRCM_a601_loop0AsicStartupDiagno "TRCM_a601_loop0AsicStartupDiagnosticFailure";
BA_ "SystemSignalLongSymbol" SG_ 2030 TRCM_a602_loop1AsicStartupDiagno "TRCM_a602_loop1AsicStartupDiagnosticFailure";
BA_ "SystemSignalLongSymbol" SG_ 2030 TRCM_a603_loop2AsicStartupDiagno "TRCM_a603_loop2AsicStartupDiagnosticFailure";
BA_ "SystemSignalLongSymbol" SG_ 2030 TRCM_a604_loop3AsicStartupDiagno "TRCM_a604_loop3AsicStartupDiagnosticFailure";
BA_ "SystemSignalLongSymbol" SG_ 2030 TRCM_a605_loop4AsicStartupDiagno "TRCM_a605_loop4AsicStartupDiagnosticFailure";
BA_ "SystemSignalLongSymbol" SG_ 2030 TRCM_a606_loop5AsicStartupDiagno "TRCM_a606_loop5AsicStartupDiagnosticFailure";
BA_ "SystemSignalLongSymbol" SG_ 2030 TRCM_a607_loop6AsicStartupDiagno "TRCM_a607_loop6AsicStartupDiagnosticFailure";
BA_ "SystemSignalLongSymbol" SG_ 2030 TRCM_a608_loop7AsicStartupDiagno "TRCM_a608_loop7AsicStartupDiagnosticFailure";
BA_ "SystemSignalLongSymbol" SG_ 2030 TRCM_a609_loop8AsicStartupDiagno "TRCM_a609_loop8AsicStartupDiagnosticFailure";
BA_ "SystemSignalLongSymbol" SG_ 2030 TRCM_a610_loop9AsicStartupDiagno "TRCM_a610_loop9AsicStartupDiagnosticFailure";
BA_ "SystemSignalLongSymbol" SG_ 2030 TRCM_a611_loop10AsicStartupDiagn "TRCM_a611_loop10AsicStartupDiagnosticFailure";
BA_ "SystemSignalLongSymbol" SG_ 2030 TRCM_a612_loop11AsicStartupDiagn "TRCM_a612_loop11AsicStartupDiagnosticFailure";
BA_ "SystemSignalLongSymbol" SG_ 2030 TRCM_a613_loop12AsicStartupDiagn "TRCM_a613_loop12AsicStartupDiagnosticFailure";
BA_ "SystemSignalLongSymbol" SG_ 2030 TRCM_a614_loop13AsicStartupDiagn "TRCM_a614_loop13AsicStartupDiagnosticFailure";
BA_ "SystemSignalLongSymbol" SG_ 2030 TRCM_a615_loop14AsicStartupDiagn "TRCM_a615_loop14AsicStartupDiagnosticFailure";
BA_ "SystemSignalLongSymbol" SG_ 2030 TRCM_a616_loop15AsicStartupDiagn "TRCM_a616_loop15AsicStartupDiagnosticFailure";
BA_ "SystemSignalLongSymbol" SG_ 2030 TRCM_a617_loop16AsicStartupDiagn "TRCM_a617_loop16AsicStartupDiagnosticFailure";
BA_ "SystemSignalLongSymbol" SG_ 2030 TRCM_a618_loop17AsicStartupDiagn "TRCM_a618_loop17AsicStartupDiagnosticFailure";
BA_ "SystemSignalLongSymbol" SG_ 2030 TRCM_a619_loop18AsicStartupDiagn "TRCM_a619_loop18AsicStartupDiagnosticFailure";
BA_ "SystemSignalLongSymbol" SG_ 2030 TRCM_a620_loop19AsicStartupDiagn "TRCM_a620_loop19AsicStartupDiagnosticFailure";
BA_ "SystemSignalLongSymbol" SG_ 2030 TRCM_a621_loop20AsicStartupDiagn "TRCM_a621_loop20AsicStartupDiagnosticFailure";
BA_ "SystemSignalLongSymbol" SG_ 2030 TRCM_a622_loop21AsicStartupDiagn "TRCM_a622_loop21AsicStartupDiagnosticFailure";
BA_ "SystemSignalLongSymbol" SG_ 2030 TRCM_a623_loop22AsicStartupDiagn "TRCM_a623_loop22AsicStartupDiagnosticFailure";
BA_ "SystemSignalLongSymbol" SG_ 2030 TRCM_a624_loop23AsicStartupDiagn "TRCM_a624_loop23AsicStartupDiagnosticFailure";
BA_ "SystemSignalLongSymbol" SG_ 2030 TRCM_a625_loop24AsicStartupDiagn "TRCM_a625_loop24AsicStartupDiagnosticFailure";
BA_ "SystemSignalLongSymbol" SG_ 2030 TRCM_a626_loop25AsicStartupDiagn "TRCM_a626_loop25AsicStartupDiagnosticFailure";
BA_ "SystemSignalLongSymbol" SG_ 2030 TRCM_a627_loop26AsicStartupDiagn "TRCM_a627_loop26AsicStartupDiagnosticFailure";
BA_ "SystemSignalLongSymbol" SG_ 2030 TRCM_a628_loop27AsicStartupDiagn "TRCM_a628_loop27AsicStartupDiagnosticFailure";
BA_ "SystemSignalLongSymbol" SG_ 2030 TRCM_a629_loop28AsicStartupDiagn "TRCM_a629_loop28AsicStartupDiagnosticFailure";
BA_ "SystemSignalLongSymbol" SG_ 2030 TRCM_a630_loop29AsicStartupDiagn "TRCM_a630_loop29AsicStartupDiagnosticFailure";
BA_ "SystemSignalLongSymbol" SG_ 2030 TRCM_a631_loop30AsicStartupDiagn "TRCM_a631_loop30AsicStartupDiagnosticFailure";
BA_ "SystemSignalLongSymbol" SG_ 2030 TRCM_a632_loop31AsicStartupDiagn "TRCM_a632_loop31AsicStartupDiagnosticFailure";
BA_ "SystemSignalLongSymbol" SG_ 2030 TRCM_a633_glacierInitialStatusFa "TRCM_a633_glacierInitialStatusFailure";
BA_ "SystemSignalLongSymbol" SG_ 2030 TRCM_a634_glacierTraceabilityRea "TRCM_a634_glacierTraceabilityReadoutA0A0Failure";
BA_ "SystemSignalLongSymbol" SG_ 2030 TRCM_a635_glacierTraceabilityRea "TRCM_a635_glacierTraceabilityReadoutB0B0Failure";
BA_ "SystemSignalLongSymbol" SG_ 2030 TRCM_a636_glacierRegisterPattern "TRCM_a636_glacierRegisterPatternWriteFailure";
BA_ "SystemSignalLongSymbol" SG_ 2030 TRCM_a637_glacierFixedPatternSel "TRCM_a637_glacierFixedPatternSelfTestFailure";
BA_ "SystemSignalLongSymbol" SG_ 2030 TRCM_a638_glacierSelfTestEFailur "TRCM_a638_glacierSelfTestEFailure";
BA_ "SystemSignalLongSymbol" SG_ 2030 TRCM_a639_glacierSelfTestFFailur "TRCM_a639_glacierSelfTestFFailure";
BA_ "SystemSignalLongSymbol" SG_ 2030 TRCM_a640_glacierAnalogSelfTestF "TRCM_a640_glacierAnalogSelfTestFailure";
BA_ "SystemSignalLongSymbol" SG_ 2030 TRCM_a641_glacierOscillatorVerif "TRCM_a641_glacierOscillatorVerificationFailure";
BA_ "SystemSignalLongSymbol" SG_ 2030 TRCM_a642_glacierFinalStatusFail "TRCM_a642_glacierFinalStatusFailure";
BA_ "SystemSignalLongSymbol" SG_ 2030 TRCM_a643_glacierOffsetVerificat "TRCM_a643_glacierOffsetVerificationFailure";
BA_ "SystemSignalLongSymbol" SG_ 2030 TRCM_a644_glacierNormalOperation "TRCM_a644_glacierNormalOperationFailure";
BA_ "Confidence" SG_ 2019 TRCM_infoIndex 1;
BA_ "Confidence" SG_ 2019 TRCM_infoBuildType 0;
BA_ "Confidence" SG_ 2019 TRCM_infoBuildConfigId 0;
BA_ "Confidence" SG_ 2019 TRCM_infoHardwareId 0;
BA_ "Confidence" SG_ 2019 TRCM_infoComponentId 0;
BA_ "Confidence" SG_ 2019 TRCM_infoPcbaId 0;
BA_ "Confidence" SG_ 2019 TRCM_infoAssemblyId 0;
BA_ "GenSigSNA" SG_ 2019 TRCM_infoAssemblyId "255";
BA_ "Confidence" SG_ 2019 TRCM_infoUsageId 0;
BA_ "Confidence" SG_ 2019 TRCM_infoSubUsageId 0;
BA_ "Confidence" SG_ 2019 TRCM_infoAppCrc 0;
BA_ "Confidence" SG_ 2019 TRCM_infoAppGitHash 0;
BA_ "Confidence" SG_ 2019 TRCM_infoBootGitHash 0;
BA_ "Confidence" SG_ 2019 TRCM_infoBootUdsProtoVersion 0;
BA_ "Confidence" SG_ 2019 TRCM_infoBootCrc 0;
BA_ "Confidence" SG_ 1641 UDS_KOSTIAsccmRequestData 1;
BA_ "Confidence" SG_ 1538 UDS_bmsRequestData 1;
BA_ "Confidence" SG_ 1579 UDS_ccRequestData 1;
BA_ "Confidence" SG_ 1539 UDS_cmpRequestData 1;
BA_ "Confidence" SG_ 1543 UDS_cmpdRequestData 1;
BA_ "Confidence" SG_ 1550 UDS_cpRequestData 1;
BA_ "Confidence" SG_ 1609 UDS_dasRequestData 1;
BA_ "Confidence" SG_ 1589 UDS_diRequestData 1;
BA_ "Confidence" SG_ 1541 UDS_difRequestData 1;
BA_ "Confidence" SG_ 1542 UDS_dirRequestData 1;
BA_ "Confidence" SG_ 1584 UDS_epas3pRequestData 1;
BA_ "Confidence" SG_ 1840 UDS_epas3sRequestData 1;
BA_ "Confidence" SG_ 1572 UDS_epblRequestData_H 1;
BA_ "Confidence" SG_ 1572 UDS_epblRequestData_L 1;
BA_ "Confidence" SG_ 1574 UDS_epbrRequestData_H 1;
BA_ "Confidence" SG_ 1574 UDS_epbrRequestData_L 1;
BA_ "Confidence" SG_ 1605 UDS_espRequestData 1;
BA_ "Confidence" SG_ 2015 UDS_functionalRequestData_0 1;
BA_ "Confidence" SG_ 2015 UDS_functionalRequestData_1 1;
BA_ "Confidence" SG_ 2015 UDS_functionalRequestData_2 1;
BA_ "Confidence" SG_ 2015 UDS_functionalRequestData_3 1;
BA_ "Confidence" SG_ 2015 UDS_functionalRequestData_4 1;
BA_ "Confidence" SG_ 2015 UDS_functionalRequestData_5 1;
BA_ "Confidence" SG_ 2015 UDS_functionalRequestData_6 1;
BA_ "Confidence" SG_ 2015 UDS_functionalRequestData_7 1;
BA_ "Confidence" SG_ 2014 UDS_functionalRequestDataCH 1;
BA_ "Confidence" SG_ 1552 UDS_hvpRequestData 1;
BA_ "Confidence" SG_ 1613 UDS_ibstRequestData 1;
BA_ "Confidence" SG_ 1560 UDS_icrRequestData 1;
BA_ "Confidence" SG_ 1603 UDS_ocs1pRequestData 1;
BA_ "Confidence" SG_ 1614 UDS_parkRequestData 1;
BA_ "Confidence" SG_ 1576 UDS_pcsRequestData 1;
BA_ "Confidence" SG_ 1634 UDS_plgRequestData 1;
BA_ "Confidence" SG_ 1568 UDS_pmRequestData 1;
BA_ "Confidence" SG_ 1604 UDS_pmfRequestData 1;
BA_ "Confidence" SG_ 1540 UDS_pmrRequestData 1;
BA_ "Confidence" SG_ 1734 UDS_ptcRequestData 1;
BA_ "Confidence" SG_ 1649 UDS_radcRequestData 1;
BA_ "Confidence" SG_ 1601 UDS_rcmRequestData 1;
BA_ "Confidence" SG_ 1664 UDS_sccmRequestData 1;
BA_ "Confidence" SG_ 1723 UDS_sdcrRequestData 1;
BA_ "Confidence" SG_ 1611 UDS_tasRequestData 1;
BA_ "Confidence" SG_ 1551 UDS_thcRequestData_H 1;
BA_ "Confidence" SG_ 1551 UDS_thcRequestData_L 1;
BA_ "Confidence" SG_ 1615 UDS_tpmsRequestData 1;
BA_ "Confidence" SG_ 1578 UDS_vcbatt1RequestData 1;
BA_ "Confidence" SG_ 1588 UDS_vcbatt2RequestData 1;
BA_ "Confidence" SG_ 1636 UDS_vcbattRequestData 1;
BA_ "Confidence" SG_ 1580 UDS_vcfront1RequestData 1;
BA_ "Confidence" SG_ 1582 UDS_vcfront2RequestData 1;
BA_ "Confidence" SG_ 1536 UDS_vcfrontRequestData 1;
BA_ "Confidence" SG_ 1570 UDS_vcleftRequestData_H 1;
BA_ "Confidence" SG_ 1570 UDS_vcleftRequestData_L 1;
BA_ "Confidence" SG_ 1544 UDS_vcrightRequestData_H 1;
BA_ "Confidence" SG_ 1544 UDS_vcrightRequestData_L 1;
BA_ "Confidence" SG_ 1546 UDS_vcsecRequestData 1;
VAL_ 2030 TRCM_matrixIndex 10 "AlertMatrix10" 9 "AlertMatrix9" 7 "AlertMatrix7" 6 "AlertMatrix6" 5 "AlertMatrix5" 4 "AlertMatrix4" 3 "AlertMatrix3" 2 "AlertMatrix2" 1 "AlertMatrix1" 0 "AlertMatrix0" ;
VAL_ 2019 TRCM_infoIndex 255 "END" 41 "SUBCOMPONENT14" 40 "SUBCOMPONENT13" 39 "SUBCOMPONENT12" 38 "SUBCOMPONENT11" 37 "SUBCOMPONENT10" 36 "SUBCOMPONENT9" 35 "SUBCOMPONENT8" 34 "SUBCOMPONENT7" 33 "SUBCOMPONENT6" 32 "SUBCOMPONENT5" 31 "SUBCOMPONENT4" 24 "SUBCOMPONENT3" 23 "SUBCOMPONENT2" 20 "UDS_PROTOCOL_BOOTCRC" 19 "VERSION_DEPRECATED" 18 "BOOTLOADER_GITHASH" 17 "APP_GITHASH" 16 "SUBCOMPONENT1" 15 "BOOTLOADER_CRC" 14 "BOOTLOADER_SVN" 13 "APP_CRC" 11 "PCBAID_ASSYID_USAGEID" 10 "BUILD_HWID_COMPONENTID" 9 "DEPRECATED_9" 8 "DEPRECATED_8" 7 "DEPRECATED_7" 6 "DEPRECATED_6" 5 "DEPRECATED_5" 4 "DEPRECATED_4" 3 "DEPRECATED_3" 2 "DEPRECATED_2" 1 "DEPRECATED_1" 0 "DEPRECATED_0" ;
VAL_ 2019 TRCM_infoBuildType 4 "INFO_MFG_BUILD" 3 "INFO_TRACEABLE_CI_BUILD" 2 "INFO_LOCAL_BUILD" 1 "INFO_PLATFORM_BUILD" 0 "INFO_UNKNOWN_BUILD" ;
VAL_ 2019 TRCM_infoAssemblyId 255 "ASSEMBLY_SNA" 1 "ASSEMBLY1" ;
